AUTOSAR XML (schema 4-0-3)
standard types defined: Boolean, uint8, UInt16, boolean
package /ArPackage_EcuInstance
  ecu instance EcuInstance_explicitinter: com-configuration-gw-time-base=0.005, com-configuration-rx-time-base=0.005, com-configuration-tx-time-base=0.005, com-enable-mdt-for-cyclic-transmission=true, sleep-mode-supported=true, wake-up-over-bus-supported=true
    can communication controller CanCommunicationController_0
    can communication connector CanCommunicationConnector_0: comm-controller=CanCommunicationController_0
  can cluster ComMChannel_CAN1
    can physical channel CanPhysicalChannel_0: comm-connectors=CanCommunicationConnector_0
      frame CanFrame_MMT_tx_200: id 0x200, from EcuInstance_explicitinter, frame-length=8, can-addressing-mode=STANDARD
        pdu ISignalIPdu_MMT_tx_200: length=8, unused-bit-pattern=0
          signal ISignal_MMT_tx_200: start 0, 8 bit, little-endian, data-type-policy=PORT-INTERFACE-DEFINITION, base-type=uint8_base
      frame CanFrame_MMT_tx_201: id 0x201, from EcuInstance_explicitinter, frame-length=8, can-addressing-mode=STANDARD
        pdu ISignalIPdu_MMT_tx_201: length=8, unused-bit-pattern=0
          signal ISignal_MMT_tx_201: start 0, 8 bit, little-endian, data-type-policy=PORT-INTERFACE-DEFINITION, base-type=uint8_base
      frame CanFrame_MMT_tx_210: id 0x210, from EcuInstance_explicitinter, frame-length=8, can-addressing-mode=STANDARD
        pdu ISignalIPdu_MMT_tx_210: length=8, unused-bit-pattern=0
          signal ISignal_MMT_tx_210: start 0, 8 bit, little-endian, data-type-policy=PORT-INTERFACE-DEFINITION
      frame CanFrame_MMT_tx_211: id 0x211, from EcuInstance_explicitinter, frame-length=8, can-addressing-mode=STANDARD
        pdu ISignalIPdu_MMT_tx_211: length=8, unused-bit-pattern=0
          signal ISignal_MMT_tx_211: start 0, 8 bit, little-endian, data-type-policy=PORT-INTERFACE-DEFINITION, base-type=uint8_base
      frame CanFrame_MMT_rx_202: id 0x202, to EcuInstance_explicitinter, frame-length=8, can-addressing-mode=STANDARD
        pdu ISignalIPdu_MMT_rx_202: length=8, unused-bit-pattern=0
          signal ISignal_MMT_rx_202: start 0, 8 bit, little-endian, data-type-policy=PORT-INTERFACE-DEFINITION, base-type=uint8_base, to EcuInstance_explicitinter
      frame CanFrame_MMT_rx_203: id 0x203, to EcuInstance_explicitinter, frame-length=8, can-addressing-mode=STANDARD
        pdu ISignalIPdu_MMT_rx_203: length=8, unused-bit-pattern=0
          signal ISignal_MMT_rx_203: start 0, 8 bit, little-endian, data-type-policy=PORT-INTERFACE-DEFINITION, base-type=uint8_base, to EcuInstance_explicitinter
      frame CanFrame_TC3U8Tx_120: id 0x120, from EcuInstance_explicitinter, frame-length=8, can-addressing-mode=STANDARD
        pdu ISignalIPdu_TC3U8Tx_120: length=8, transmission-mode-condition{data-filter=data-filter-type=ALWAYS, i-signal-in-i-pdu=ISignalIPdu_TC3U8Tx_120/ISignalToIPduMapping_TC3U8Tx}, transmission-mode-true-timing=event-controlled-timing={number-of-repetitions=0, repetition-period=0.0}, unused-bit-pattern=0
          signal ISignal_TC3U8Tx_120: start 0, 8 bit, little-endian, system signal SystemSignal_TC3U8TX_120, data-type-policy=PORT-INTERFACE-DEFINITION, transfer-property=TRIGGERED
      frame CanFrame_TC5ArrTx_121: id 0x121, from EcuInstance_explicitinter, frame-length=8, can-addressing-mode=STANDARD
        pdu ISignalIPdu_TC5ArrTx_121: length=8, transmission-mode-condition{data-filter=data-filter-type=ALWAYS, i-signal-in-i-pdu=ISignalToIPduMapping_TC5ArrTx}, transmission-mode-true-timing=event-controlled-timing={number-of-repetitions=0, repetition-period=0.0}, unused-bit-pattern=0
          mapping ISignalToIPduMapping_TC5ArrTx: i-signal-group=ISignalGroup_TC5ArrTx_121, packing-byte-order=little-endian, start-position=0, transfer-property=TRIGGERED
          mapping ISignalToIPduMapping_TC5Arr0Tx: packing-byte-order=little-endian, start-position=0, transfer-property=TRIGGERED
          mapping ISignalToIPduMapping_TC5Arr1Tx: packing-byte-order=little-endian, start-position=8
          mapping ISignalToIPduMapping_TC5Arr2Tx: packing-byte-order=little-endian, start-position=16
      frame CanFrame_TC6U8Rx_122: id 0x122, to EcuInstance_explicitinter, frame-length=8, can-addressing-mode=STANDARD
        pdu ISignalIPdu_TC6U8Rx_122: length=8, unused-bit-pattern=0
          signal ISignal_TC6U8Rx_122: start 0, 8 bit, little-endian, system signal SystemSignal_TC6U8RX_122, data-type-policy=PORT-INTERFACE-DEFINITION, transfer-property=TRIGGERED, to EcuInstance_explicitinter
      frame CanFrame_TC7Arr8Rx_123: id 0x123, to EcuInstance_explicitinter, frame-length=8, can-addressing-mode=STANDARD
        pdu ISignalIPdu_TC7Arr8Rx_123: length=8, unused-bit-pattern=0
          mapping ISignalToIPduMapping_TC7ArrRx: i-signal-group=ISignalGroup_TC7ArrRx_123, packing-byte-order=little-endian, start-position=0, transfer-property=TRIGGERED
          mapping ISignalToIPduMapping_TC7Arr0Rx: packing-byte-order=little-endian, start-position=0, transfer-property=TRIGGERED
          mapping ISignalToIPduMapping_TC7Arr1Rx: packing-byte-order=little-endian, start-position=8
          mapping ISignalToIPduMapping_TC7Arr2Rx: packing-byte-order=little-endian, start-position=16
      frame CanFrame_TC13U8Tx_126: id 0x126, from EcuInstance_explicitinter, frame-length=8, can-addressing-mode=STANDARD
        pdu ISignalIPdu_TC13U8Tx_126: length=8, transmission-mode-condition{data-filter=data-filter-type=ALWAYS, i-signal-in-i-pdu=ISignalToIPduMapping_TC13U8Tx}, transmission-mode-true-timing=event-controlled-timing={number-of-repetitions=0, repetition-period=0.0}, unused-bit-pattern=0
          signal ISignal_TC13U8Tx_126: start 0, 8 bit, little-endian, data-type-policy=PORT-INTERFACE-DEFINITION, transfer-property=TRIGGERED
      frame CanFrame_TC14Arr8Tx_127: id 0x127, from EcuInstance_explicitinter, frame-length=8, can-addressing-mode=STANDARD
        pdu ISignalIPdu_TC14Arr8Tx_127: length=8, transmission-mode-condition{data-filter=data-filter-type=ALWAYS, i-signal-in-i-pdu=ISignalToIPduMapping_TC14ArrTx}, transmission-mode-true-timing=event-controlled-timing={number-of-repetitions=0, repetition-period=0.0}, unused-bit-pattern=0
          mapping ISignalToIPduMapping_TC14ArrTx: i-signal-group=ISignalGroup_TC14Arr8Tx_127, packing-byte-order=little-endian, start-position=0, transfer-property=TRIGGERED
          mapping ISignalToIPduMapping_TC14Arr0Tx: packing-byte-order=little-endian, start-position=0, transfer-property=TRIGGERED
          mapping ISignalToIPduMapping_TC14Arr1Tx: packing-byte-order=little-endian, start-position=8
          mapping ISignalToIPduMapping_TC14Arr2Tx: packing-byte-order=little-endian, start-position=16
      frame CanFrame_TC15U8RxInv_128: id 0x128, to EcuInstance_explicitinter, frame-length=8, can-addressing-mode=STANDARD
        pdu ISignalIPdu_TC15U8RxInv_128: length=8, unused-bit-pattern=0
          signal ISignal_TC15U8RxInv_128: start 0, 8 bit, little-endian, data-type-policy=PORT-INTERFACE-DEFINITION, transfer-property=TRIGGERED, to EcuInstance_explicitinter
      frame CanFrame_TC16U8RxInvReplace_129: id 0x129, to EcuInstance_explicitinter, frame-length=8, can-addressing-mode=STANDARD
        pdu ISignalIPdu_TC16U8RxInvReplace_129: length=8, unused-bit-pattern=0
          signal ISignal_TC16U8RxInvReplace_129: start 0, 8 bit, little-endian, data-type-policy=PORT-INTERFACE-DEFINITION, transfer-property=TRIGGERED, to EcuInstance_explicitinter
      frame CanFrame_TC17ArrRx_12A: id 0x12A, to EcuInstance_explicitinter, frame-length=8, can-addressing-mode=STANDARD
        pdu ISignalIPdu_TC17ArrRx_12A: length=8, unused-bit-pattern=0
          mapping ISignalToIPduMapping_TC17ArrRx: i-signal-group=ISignalGroup_TC17Arr8Rx_12A, packing-byte-order=little-endian, start-position=0, transfer-property=TRIGGERED
          mapping ISignalToIPduMapping_TC17Arr0Rx: packing-byte-order=little-endian, start-position=0, transfer-property=TRIGGERED
          mapping ISignalToIPduMapping_TC17Arr1Rx: packing-byte-order=little-endian, start-position=8
      frame CanFrame_TC18ArrRx_12B: id 0x12B, to EcuInstance_explicitinter, frame-length=8, can-addressing-mode=STANDARD
        pdu ISignalIPdu_TC18ArrRx_12B: length=8, unused-bit-pattern=0
          mapping ISignalToIPduMapping_TC18ArrRx: i-signal-group=ISignalGroup_TC18Arr8Rx_12B, packing-byte-order=little-endian, start-position=0, transfer-property=TRIGGERED
          mapping ISignalToIPduMapping_TC18Arr0Rx: packing-byte-order=little-endian, start-position=0, transfer-property=TRIGGERED
          mapping ISignalToIPduMapping_TC18Arr1Rx: packing-byte-order=little-endian, start-position=8
          mapping ISignalToIPduMapping_TC18Arr2Rx: packing-byte-order=little-endian, start-position=16
      frame CanFrame_TC19U8Tx_12C: id 0x12C, from EcuInstance_explicitinter, frame-length=8, can-addressing-mode=STANDARD
        pdu ISignalIPdu_TC19U8Tx_12C: length=8, transmission-mode-condition{data-filter=data-filter-type=ALWAYS, i-signal-in-i-pdu=ISignalToIPduMapping_TC19Tx}, transmission-mode-true-timing=event-controlled-timing={number-of-repetitions=0, repetition-period=0.0}, unused-bit-pattern=0
          signal ISignal_TC19U8Tx_12C: start 0, 8 bit, little-endian, data-type-policy=PORT-INTERFACE-DEFINITION, transfer-property=TRIGGERED
      frame CanFrame_TC21U8Tx_250: id 0x250, from EcuInstance_explicitinter, frame-length=8, can-addressing-mode=STANDARD
        pdu ISignalIPdu_TC21U8Tx_250: length=8, transmission-mode-condition{data-filter=data-filter-type=ALWAYS, i-signal-in-i-pdu=ISignalToIPduMapping_TC21}, transmission-mode-true-timing=event-controlled-timing={number-of-repetitions=0, repetition-period=0.0}, unused-bit-pattern=0
          signal ISignal_TC21U8Tx_250: start 0, 8 bit, little-endian, data-type-policy=PORT-INTERFACE-DEFINITION, transfer-property=TRIGGERED
      frame CanFrame_TC23U8Tx_149: id 0x149, from EcuInstance_explicitinter, frame-length=8, can-addressing-mode=STANDARD
        pdu ISignalIPdu_TC23U8Tx_149: length=8, transmission-mode-condition{data-filter=data-filter-type=ALWAYS, i-signal-in-i-pdu=ISignalToIPduMapping_TC23}, transmission-mode-true-timing=event-controlled-timing={number-of-repetitions=0, repetition-period=0.0}, unused-bit-pattern=0
          signal ISignal_TC23U8Tx_149: start 0, 8 bit, little-endian, data-type-policy=PORT-INTERFACE-DEFINITION, transfer-property=TRIGGERED
      frame CanFrame_TC26Arr8Tx_12F: id 0x12F, from EcuInstance_explicitinter, frame-length=8, can-addressing-mode=STANDARD
        pdu ISignalIPdu_TC26Arr8Tx_12F: length=8, transmission-mode-condition{data-filter=data-filter-type=ALWAYS, i-signal-in-i-pdu=ISignalToIPduMapping_TC26ArrTx}, transmission-mode-true-timing=event-controlled-timing={number-of-repetitions=0, repetition-period=0.0}, unused-bit-pattern=0
          mapping ISignalToIPduMapping_TC26ArrTx: i-signal-group=ISignalGroup_TC26Arr8Tx_12F, packing-byte-order=little-endian, start-position=0, transfer-property=TRIGGERED
          mapping ISignalToIPduMapping_TC26Arr0Tx: packing-byte-order=little-endian, start-position=0, transfer-property=TRIGGERED
          mapping ISignalToIPduMapping_TC26Arr1Tx: packing-byte-order=little-endian, start-position=8
      frame CanFrame_TC28Arr8Tx_252: id 0x252, from EcuInstance_explicitinter, frame-length=8, can-addressing-mode=STANDARD
        pdu ISignalIPdu_TC28Arr8Tx_252: length=8, transmission-mode-condition{data-filter=data-filter-type=ALWAYS, i-signal-in-i-pdu=ISignalToIPduMapping_TC28ArrTx}, transmission-mode-true-timing=event-controlled-timing={number-of-repetitions=0, repetition-period=0.0}, unused-bit-pattern=0
          mapping ISignalToIPduMapping_TC28ArrTx: i-signal-group=ISignalGroup_TC28Arr8Tx_252, packing-byte-order=little-endian, start-position=0, transfer-property=TRIGGERED
          mapping ISignalToIPduMapping_TC28Arr0Tx: packing-byte-order=little-endian, start-position=0, transfer-property=TRIGGERED
          mapping ISignalToIPduMapping_TC28Arr1Tx: packing-byte-order=little-endian, start-position=8
      frame CanFrame_TC30Arr8Tx_14B: id 0x14B, from EcuInstance_explicitinter, frame-length=8, can-addressing-mode=STANDARD
        pdu ISignalIPdu_TC30Arr8Tx_14B: length=8, transmission-mode-condition{data-filter=data-filter-type=ALWAYS, i-signal-in-i-pdu=ISignalToIPduMapping_TC30ArrTx}, transmission-mode-true-timing=event-controlled-timing={number-of-repetitions=0, repetition-period=0.0}, unused-bit-pattern=0
          mapping ISignalToIPduMapping_TC30ArrTx: i-signal-group=ISignalGroup_TC30Arr8Tx_14B, packing-byte-order=little-endian, start-position=0, transfer-property=TRIGGERED
          mapping ISignalToIPduMapping_TC30Arr0Tx: packing-byte-order=little-endian, start-position=0, transfer-property=TRIGGERED
          mapping ISignalToIPduMapping_TC30Arr1Tx: packing-byte-order=little-endian, start-position=8
      frame CanFrame_TC34U8Rx_132: id 0x132, to EcuInstance_explicitinter, frame-length=8, can-addressing-mode=STANDARD
        pdu ISignalIPdu_TC34U8Rx_132: length=8, unused-bit-pattern=0
          signal ISignal_TC34U8Rx_132: start 0, 8 bit, little-endian, data-type-policy=PORT-INTERFACE-DEFINITION, transfer-property=TRIGGERED, to EcuInstance_explicitinter
      frame CanFram_TC36U8Tx_133: id 0x133, from EcuInstance_explicitinter, frame-length=8, can-addressing-mode=STANDARD
        pdu ISignalIPdu_TC36U8Tx_133: length=8, transmission-mode-condition{data-filter=data-filter-type=ALWAYS, i-signal-in-i-pdu=ISignalToIPduMapping_TC36}, transmission-mode-true-timing=event-controlled-timing={number-of-repetitions=0, repetition-period=0.0}, unused-bit-pattern=0
          signal ISignal_TC36U8Tx_133: start 0, 8 bit, little-endian, data-type-policy=PORT-INTERFACE-DEFINITION, transfer-property=TRIGGERED
      frame CanFrame_TC37U8Tx_254: id 0x254, from EcuInstance_explicitinter, frame-length=8, can-addressing-mode=STANDARD
        pdu ISignalIPdu_TC37U8Tx_254: length=8, transmission-mode-condition{data-filter=data-filter-type=ALWAYS, i-signal-in-i-pdu=ISignalToIPduMapping_TC37}, transmission-mode-true-timing=event-controlled-timing={number-of-repetitions=0, repetition-period=0.0}, unused-bit-pattern=0
          signal ISignal_TC37U8Tx_254: start 0, 8 bit, little-endian, data-type-policy=PORT-INTERFACE-DEFINITION, transfer-property=TRIGGERED
      frame CanFrame_TC38U8Rx_134: id 0x134, to EcuInstance_explicitinter, frame-length=8, can-addressing-mode=STANDARD
        pdu ISignalIPdu_TC38U8Rx_134: length=8, unused-bit-pattern=0
          signal ISignal_TC38U8Rx_134: start 0, 8 bit, little-endian, data-type-policy=PORT-INTERFACE-DEFINITION, transfer-property=TRIGGERED, to EcuInstance_explicitinter
      frame CanFrame_TC32Arr8Rx_131: id 0x131, to EcuInstance_explicitinter, frame-length=8, can-addressing-mode=STANDARD
        pdu ISignalIPdu_TC32Arr8Rx_131: length=8, unused-bit-pattern=0
          mapping ISignalToIPduMapping_TC32ArrRx: i-signal-group=ISignalGroup_TC32Arr8Rx_131, packing-byte-order=little-endian, start-position=0, transfer-property=TRIGGERED
          mapping ISignalToIPduMapping_TC32Arr0Rx: packing-byte-order=little-endian, start-position=0, transfer-property=TRIGGERED
          mapping ISignalToIPduMapping_TC32Arr1Rx: packing-byte-order=little-endian, start-position=8
      frame CanFrame_TC22U8Tx_251: id 0x251, from EcuInstance_explicitinter, frame-length=8, can-addressing-mode=STANDARD
        pdu ISignalIPdu_TC22U8Tx_251: length=8, transmission-mode-condition{data-filter=data-filter-type=ALWAYS, i-signal-in-i-pdu=ISignalToIPduMapping_TC22U8Tx}, transmission-mode-true-timing=event-controlled-timing={number-of-repetitions=0, repetition-period=0.0}, unused-bit-pattern=0
          signal ISignal_TC22U8Tx_251: start 0, 8 bit, little-endian, data-type-policy=PORT-INTERFACE-DEFINITION, transfer-property=TRIGGERED
      frame CanFrame_TC20U8Tx_12D: id 0x12D, from EcuInstance_explicitinter, frame-length=8, can-addressing-mode=STANDARD
        pdu ISignalIPdu_TC20U8Tx_12D: length=8, transmission-mode-condition{data-filter=data-filter-type=ALWAYS, i-signal-in-i-pdu=ISignalToIPduMapping_TC20U8Tx}, transmission-mode-true-timing=event-controlled-timing={number-of-repetitions=0, repetition-period=0.0}, unused-bit-pattern=0
          signal ISignal_TC20U8Tx_12D: start 0, 8 bit, little-endian, data-type-policy=PORT-INTERFACE-DEFINITION, transfer-property=TRIGGERED
      frame CanFrame_TC24U8Tx_14A: id 0x14A, from EcuInstance_explicitinter, frame-length=8, can-addressing-mode=STANDARD
        pdu ISignalIPdu_TC24U8Tx_14A: length=8, transmission-mode-condition{data-filter=data-filter-type=ALWAYS, i-signal-in-i-pdu=ISignalToIPduMapping_TC24U8Tx}, transmission-mode-true-timing=event-controlled-timing={number-of-repetitions=0, repetition-period=0.0}, unused-bit-pattern=0
          signal ISignal_TC24U8Tx_14A: start 0, 8 bit, little-endian, data-type-policy=PORT-INTERFACE-DEFINITION, transfer-property=TRIGGERED
      frame CanFrame_TC27Arr8Tx_130: id 0x130, from EcuInstance_explicitinter, frame-length=8, can-addressing-mode=STANDARD
        pdu ISignalIPdu_TC27Arr8Tx_130: length=8, transmission-mode-condition{data-filter=data-filter-type=ALWAYS, i-signal-in-i-pdu=ISignalToIPduMapping_TC27ArrTx}, transmission-mode-true-timing=event-controlled-timing={number-of-repetitions=0, repetition-period=0.0}, unused-bit-pattern=0
          mapping ISignalToIPduMapping_TC27ArrTx: i-signal-group=ISignalGroup_TC27Arr8Tx_130, packing-byte-order=little-endian, start-position=0, transfer-property=TRIGGERED
          mapping ISignalToIPduMapping_TC27Arr0Tx: packing-byte-order=little-endian, start-position=0, transfer-property=TRIGGERED
          mapping ISignalToIPduMapping_TC27Arr1Tx: packing-byte-order=little-endian, start-position=8, transfer-property=TRIGGERED
          mapping ISignalToIPduMapping_TC27Arr2Tx: packing-byte-order=little-endian, start-position=16, transfer-property=TRIGGERED
      frame CanFrame_TC29Arr8Tx_253: id 0x253, from EcuInstance_explicitinter, frame-length=8, can-addressing-mode=STANDARD
        pdu ISignalIPdu_TC29Arr8Tx_253: length=8, transmission-mode-condition{data-filter=data-filter-type=ALWAYS, i-signal-in-i-pdu=ISignalToIPduMappingTC29Arr8Tx}, transmission-mode-true-timing=event-controlled-timing={number-of-repetitions=0, repetition-period=0.0}, unused-bit-pattern=0
          mapping ISignalToIPduMappingTC29Arr8Tx: i-signal-group=ISignalGroup_TC29Arr8Tx_253, packing-byte-order=little-endian, start-position=0, transfer-property=TRIGGERED
          mapping ISignalToIPduMappingTC29Arr0Tx: packing-byte-order=little-endian, start-position=0, transfer-property=TRIGGERED
          mapping ISignalToIPduMappingTC29Arr1Tx: packing-byte-order=little-endian, start-position=8
      frame CanFrame_TC31Arr8Tx_14C: id 0x14C, from EcuInstance_explicitinter, frame-length=8, can-addressing-mode=STANDARD
        pdu ISignalIPdu_TC31Arr8Tx_14C: length=8, transmission-mode-condition{data-filter=data-filter-type=ALWAYS, i-signal-in-i-pdu=ISignalToIPduMapping_TC28ArrTx}, transmission-mode-true-timing=event-controlled-timing={number-of-repetitions=0, repetition-period=0.0}, unused-bit-pattern=0
          mapping ISignalToIPduMapping_TC31Arr8Tx: i-signal-group=ISignalGroup_TC31Arr8Tx_14C, packing-byte-order=little-endian, start-position=0, transfer-property=TRIGGERED
          mapping ISignalToIPduMapping_TC31Arr0Tx: packing-byte-order=little-endian, start-position=0, transfer-property=TRIGGERED
          mapping ISignalToIPduMapping_TC31Arr1Tx: packing-byte-order=little-endian, start-position=8
      frame CanFrame_TC40U8Rx_136: id 0x136, to EcuInstance_explicitinter, frame-length=8, can-addressing-mode=STANDARD
        pdu ISignalIPdu_TC40U8Rx_136: length=8, unused-bit-pattern=0
          signal ISignal_TC40U8Rx_136: start 0, 8 bit, little-endian, data-type-policy=PORT-INTERFACE-DEFINITION, transfer-property=TRIGGERED, to EcuInstance_explicitinter
      frame CanFrame_TC41U8Rx_137: id 0x137, to EcuInstance_explicitinter, frame-length=8, can-addressing-mode=STANDARD
        pdu ISignalIPdu_TC41U8Rx_137: length=8, unused-bit-pattern=0
          signal ISignal_TC41U8Rx_137: start 0, 8 bit, little-endian, data-type-policy=PORT-INTERFACE-DEFINITION, transfer-property=TRIGGERED, to EcuInstance_explicitinter
      frame CanFrame_TC39Arr8Rx_135: id 0x135, to EcuInstance_explicitinter, frame-length=8, can-addressing-mode=STANDARD
        pdu ISignalIPdu_TC39Arr8Rx_135: length=8, unused-bit-pattern=0
          mapping ISignalToIPduMapping_TC39ArrRx: i-signal-group=ISignalGroup_TC39Arr8Rx_135, packing-byte-order=little-endian, start-position=0, transfer-property=TRIGGERED
          mapping ISignalToIPduMapping_TC39Arr0Rx: packing-byte-order=little-endian, start-position=0, transfer-property=TRIGGERED
          mapping ISignalToIPduMapping_TC39Arr1Rx: packing-byte-order=little-endian, start-position=8
          mapping ISignalToIPduMapping_TC39Arr2Rx: packing-byte-order=little-endian, start-position=16
      frame CanFrame_TC8DynArruint8_124: id 0x124, from EcuInstance_explicitinter, frame-length=8, can-addressing-mode=STANDARD
        pdu ISignalIPdu_TC8DynArruint8_124: length=8, transmission-mode-condition{data-filter=data-filter-type=ALWAYS, i-signal-in-i-pdu=ISignalToIPduMapping_TC8DynArruint8}, transmission-mode-true-timing=event-controlled-timing={number-of-repetitions=0, repetition-period=0.0}, unused-bit-pattern=0
          signal ISignal_TC8DynArruint8_124: start 0, 64 bit, little-endian, data-type-policy=PORT-INTERFACE-DEFINITION, dynamic-length=true, transfer-property=TRIGGERED
      frame CanFrame_TC9DynArruint8_125: id 0x125, to EcuInstance_explicitinter, frame-length=8, can-addressing-mode=STANDARD
        pdu ISignalIPdu_TC9DynArruint8_125: length=8, unused-bit-pattern=0
          signal ISignal_TC9DynArruint8_125: start 0, 64 bit, little-endian, data-type-policy=PORT-INTERFACE-DEFINITION, dynamic-length=true, transfer-property=TRIGGERED, to EcuInstance_explicitinter
      frame CanFrame_TC25U8RX_12E: id 0x12E, to EcuInstance_explicitinter, frame-length=8, can-addressing-mode=STANDARD
        pdu ISignalIPdu_TC25U8RX_12E: length=8, unused-bit-pattern=0
          signal ISignal_TC25U8RX_12E: start 0, 8 bit, little-endian, data-type-policy=PORT-INTERFACE-DEFINITION, transfer-property=TRIGGERED, to EcuInstance_explicitinter
      frame CanFrame_NmPdu_RX: id 0x7F0, to EcuInstance_explicitinter, frame-length=8, can-addressing-mode=STANDARD
        nm pdu NmPdu_RX: length=8, nm-data-information=false, nm-vote-information=false, unused-bit-pattern=0
      frame CanFrame_NmPdu_TX: id 0x7F1, from EcuInstance_explicitinter, frame-length=8, can-addressing-mode=STANDARD
        nm pdu NmPdu_TX: length=8, nm-data-information=false, nm-vote-information=false, unused-bit-pattern=0
package /ArPackage_ComM
  impl type ComM_ModeType: category=VALUE, base-type=uint8_base, data-constr=DataConstr_0
  data constr DataConstr_0
  client server interface ComM_UserRequest: is-service=true, service-kind=COM-MANAGER
    4 x operation:
      RequestComMode: possible-error=[ComM_UserRequest/E_NOT_OK, E_MODE_LIMITATION]
        arg ComMode: type=ComM_ModeType, direction=IN
      GetCurrentComMode: possible-error=ComM_UserRequest/E_NOT_OK
        arg ComMode: type=ComM_ModeType, direction=OUT
      GetMaxComMode: possible-error=ComM_UserRequest/E_NOT_OK
        arg ComMode: type=ComM_ModeType, direction=OUT
      GetRequestedComMode: possible-error=ComM_UserRequest/E_NOT_OK
        arg ComMode: type=ComM_ModeType, direction=OUT
    error E_NOT_OK: error-code=1
    error E_MODE_LIMITATION: error-code=2
  client server interface ComM_ECUModeLimitation: is-service=true, service-kind=COM-MANAGER
    4 x operation, all with possible-error=ComM_ECUModeLimitation/E_NOT_OK:
      LimitECUToNoComMode
        arg Status: type=Boolean, direction=IN
      ReadInhibitCounter
        arg CounterValue: type=UInt16, direction=OUT
      ResetInhibitCounter
      SetECUGroupClassification
        arg Status: type=ComM_InhibitionStatusType, direction=IN
    error E_NOT_OK: error-code=1
  data type mapping set DataTypeMappingSet_0: mode-request-type-map{implementation-data-type=ComM_ModeType, mode-group=ComMMode}
  mode declaration group ComMMode: initial-mode=COMM_NO_COMMUNICATION
    mode COMM_NO_COMMUNICATION
    mode COMM_SILENT_COMMUNICATION
    mode COMM_FULL_COMMUNICATION
  mode switch interface ComM_CurrentMode: is-service=true, service-kind=COM-MANAGER
    mode group currentMode: type=ComMMode
  sender receiver interface ComM_CurrentChannelRequest
    data fullComRequestors: type=ComM_UserHandleArrayType
  impl type ComM_UserHandleArrayType: category=STRUCTURE
    element numberOfRequesters: category=VALUE, base-type=uint8_base
    element handleArray: implementation-data-type=ComM_UserHandleType_array
  impl type ComM_UserHandleType_array: category=ARRAY
  client server interface ComM_ChannelWakeup: is-service=true, service-kind=COM-MANAGER
    operation PreventWakeUp: possible-error=ComM_ChannelWakeup/E_NOT_OK
      arg Status: type=Boolean, direction=IN
    error E_NOT_OK: error-code=1
  client server interface ComM_ChannelLimitation: is-service=true, service-kind=COM-MANAGER
    operation LimitChannelToNoComMode: possible-error=ComM_ChannelLimitation/E_NOT_OK
      arg Status: type=Boolean, direction=IN
    operation GetInhibitionStatus: possible-error=ComM_ChannelLimitation/E_NOT_OK
      arg Status: type=ComM_InhibitionStatusType, direction=OUT
    error E_NOT_OK: error-code=1
  impl type ComM_InhibitionStatusType: category=VALUE, base-type=uint8_base
  data constr DataConstr_2
  impl type ComM_UserHandleType: category=VALUE
  data constr DataConstr_1
package /ArPackage_NvM
  client server interface NvMAdmin: is-service=true, service-kind=NON-VOLATILE-RAM-MANAGER
    operation SetBlockProtection: possible-error=NvMAdmin/E_NOT_OK
      arg ArgumentDataPrototype_0: type=boolean, direction=IN
    error E_NOT_OK: error-code=1
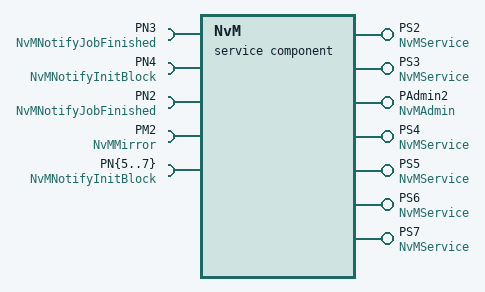
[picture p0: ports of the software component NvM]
  service sw component type NvM
    7 x provide port:
      PS2: provided-interface=NvMService
        provided-com-specs:
          queue-length=1
          operation=SetDataIndex, queue-length=1
          operation=GetDataIndex, queue-length=1
          operation=SetRamBlockStatus, queue-length=1
          operation=ReadBlock, queue-length=1
          operation=WriteBlock, queue-length=1
          operation=RestoreBlockDefaults, queue-length=1
          operation=EraseBlock, queue-length=1
          operation=InvalidateNvBlock, queue-length=1
      PS3: provided-interface=NvMService
        provided-com-specs:
          operation=GetErrorStatus, queue-length=1
          operation=SetDataIndex, queue-length=1
          operation=GetDataIndex, queue-length=1
          operation=SetRamBlockStatus, queue-length=1
          operation=ReadBlock, queue-length=1
          operation=WriteBlock, queue-length=1
          operation=RestoreBlockDefaults, queue-length=1
          operation=EraseBlock, queue-length=1
          operation=InvalidateNvBlock, queue-length=1
      PAdmin2: server-com-spec{operation=SetBlockProtection, queue-length=1}, provided-interface=NvMAdmin
      PS4: provided-interface=NvMService
        provided-com-specs:
          operation=GetErrorStatus, queue-length=1
          operation=SetDataIndex, queue-length=1
          operation=GetDataIndex, queue-length=1
          operation=SetRamBlockStatus, queue-length=1
          operation=ReadBlock, queue-length=1
          operation=WriteBlock, queue-length=1
          operation=RestoreBlockDefaults, queue-length=1
          operation=EraseBlock, queue-length=1
          operation=InvalidateNvBlock, queue-length=1
          operation=CancelJobs, queue-length=1
      PS5: provided-interface=NvMService
        provided-com-specs:
          operation=GetErrorStatus, queue-length=1
          operation=SetDataIndex, queue-length=1
          operation=GetDataIndex, queue-length=1
          operation=SetRamBlockStatus, queue-length=1
          operation=ReadBlock, queue-length=1
          operation=WriteBlock, queue-length=1
          operation=RestoreBlockDefaults, queue-length=1
          operation=EraseBlock, queue-length=1
          operation=InvalidateNvBlock, queue-length=1
          operation=CancelJobs, queue-length=1
      PS6: provided-interface=NvMService
        provided-com-specs:
          operation=GetErrorStatus, queue-length=1
          operation=SetDataIndex, queue-length=1
          operation=GetDataIndex, queue-length=1
          operation=SetRamBlockStatus, queue-length=1
          operation=ReadBlock, queue-length=1
          operation=WriteBlock, queue-length=1
          operation=RestoreBlockDefaults, queue-length=1
          operation=EraseBlock, queue-length=1
          operation=InvalidateNvBlock, queue-length=1
          operation=CancelJobs, queue-length=1
      PS7: provided-interface=NvMService
        provided-com-specs:
          operation=GetErrorStatus, queue-length=1
          operation=SetDataIndex, queue-length=1
          operation=GetDataIndex, queue-length=1
          operation=SetRamBlockStatus, queue-length=1
          operation=ReadBlock, queue-length=1
          operation=WriteBlock, queue-length=1
          operation=RestoreBlockDefaults, queue-length=1
          operation=EraseBlock, queue-length=1
          operation=InvalidateNvBlock, queue-length=1
          operation=CancelJobs, queue-length=1
    7 x require port:
      PN3: client-com-spec=JobFinished, required-interface=NvMNotifyJobFinished
      PN4: client-com-spec=InitBlock, required-interface=NvMNotifyInitBlock
      PN2: client-com-spec=JobFinished, required-interface=NvMNotifyJobFinished
      PM2: required-com-specs=[ReadRamBlockFromNvm, WriteRamBlockToNvm], required-interface=NvMMirror
      PN{5..7}: client-com-spec=InitBlock, required-interface=NvMNotifyInitBlock
    behavior IB_NvM: handle-termination-and-restart=CAN-BE-TERMINATED-AND-RESTARTED
      10 x operation invoked event:
        OperationInvokedEvent_0: start-on-event=GetErrorStatus, operation=PS2.GetErrorStatus
        OperationInvokedEvent_1: start-on-event=SetDataIndex, operation=PS2.SetDataIndex
        OperationInvokedEvent_2: start-on-event=GetDataIndex, operation=PS2.GetDataIndex
        OperationInvokedEvent_3: start-on-event=SetRamBlockStatus, operation=PS2.SetRamBlockStatus
        OperationInvokedEvent_4: start-on-event=ReadBlock, operation=PS2.ReadBlock
        OperationInvokedEvent_5: start-on-event=WriteBlock, operation=PS2.WriteBlock
        OperationInvokedEvent_6: start-on-event=RestoreBlockDefaults, operation=PS2.RestoreBlockDefaults
        OperationInvokedEvent_7: start-on-event=EraseNvBlock, operation=PS2.EraseBlock
        OperationInvokedEvent_8: start-on-event=InvalidateNvBlock, operation=PS2.InvalidateNvBlock
        OperationInvokedEvent_9: start-on-event=SetBlockProtection, operation=PAdmin2.SetBlockProtection
      port-api-options:
        {enable-take-address=false, indirect-api=false, port-defined-argument-value{value=Block2:2, value-type=NvM_BlockIdType}, port=PS2}
        {enable-take-address=false, indirect-api=false, port-defined-argument-value{value=Block3:3, value-type=NvM_BlockIdType}, port=PS3}
        {enable-take-address=false, indirect-api=false, port-defined-argument-value{value=Block2:2, value-type=NvM_BlockIdType}, port=PAdmin2}
      10 x runnable, all with can-be-invoked-concurrently=true:
        GetErrorStatus: symbol=NvM_GetErrorStatus
        SetDataIndex: symbol=NvM_SetDataIndex
        GetDataIndex: symbol=NvM_GetDataIndex
        SetRamBlockStatus: symbol=NvM_SetRamBlockStatus
        ReadBlock: symbol=NvM_ReadBlock
        WriteBlock: symbol=NvM_WriteBlock
        RestoreBlockDefaults: symbol=NvM_RestoreBlockDefaults
        EraseNvBlock: symbol=NvM_EraseNvBlock
        InvalidateNvBlock: symbol=NvM_InvalidateNvBlock
        SetBlockProtection: symbol=NvM_SetBlockProtection
  client server interface NvMService: is-service=true, service-kind=NON-VOLATILE-RAM-MANAGER
    10 x operation, all with possible-error=NvMService/E_NOT_OK:
      GetErrorStatus
        arg ArgumentDataPrototype_0: type=NvM_RequestResultType, direction=OUT
      SetDataIndex
        arg ArgumentDataPrototype_0: type=ArPackage_NvM/uint8, direction=IN
      GetDataIndex
        arg ArgumentDataPrototype_0: type=ArPackage_NvM/uint8, direction=OUT
      SetRamBlockStatus
        arg ArgumentDataPrototype_0: type=ArPackage_NvM/uint8, direction=IN
      ReadBlock
        arg ArgumentDataPrototype_0: type=Arr8, direction=IN, server-argument-impl-policy=USE-VOID
      WriteBlock
        arg ArgumentDataPrototype_0: type=Arr8, direction=IN, server-argument-impl-policy=USE-VOID
      RestoreBlockDefaults
        arg ArgumentDataPrototype_0: type=Arr8, direction=IN, server-argument-impl-policy=USE-VOID
      EraseBlock
      InvalidateNvBlock
      CancelJobs
    error E_NOT_OK: error-code=1
  impl type NvM_RequestResultType: category=VALUE, base-type=uint8_base, compu {0=NVM_REQ_OK (EngObject), 1=NVM_REQ_NOT_OK, 2=NVM_REQ_PENDING, 3=NVM_REQ_INTEGRITY_FAILED, 4=NVM_REQ_BLOCK_SKIPPED, 5=NVM_REQ_NV_INVALIDATED, 6=NVM_REQ_CANCELED, 7=NVM_REQ_REDUNDANCY_FAILED, 8=NVM_REQ_RESTORED_FROM_ROM}
  client server interface NvMNotifyJobFinished: is-service=true, service-kind=NON-VOLATILE-RAM-MANAGER
    operation JobFinished
      arg ArgumentDataPrototype_0: type=ArPackage_NvM/uint8, direction=IN
      arg ArgumentDataPrototype_1: type=NvM_RequestResultType, direction=IN
  impl type Arr8: category=ARRAY
    element ImplementationDataTypeElement_0: category=VALUE, array-size=8, array-size-semantics=FIXED-SIZE, base-type=uint8_base
  client server interface NvMMirror: is-service=true, service-kind=NON-VOLATILE-RAM-MANAGER
    operation ReadRamBlockFromNvm: possible-error=NvMMirror/E_NOT_OK
      arg ArgumentDataPrototype_0: type=Arr8, direction=IN, server-argument-impl-policy=USE-VOID
    operation WriteRamBlockToNvm: possible-error=NvMMirror/E_NOT_OK
      arg ArgumentDataPrototype_0: type=Arr8, direction=IN, server-argument-impl-policy=USE-VOID
    error E_NOT_OK: error-code=1
  impl type NvM_BlockIdType: category=VALUE
  client server interface NvMNotifyInitBlock: is-service=true, service-kind=NON-VOLATILE-RAM-MANAGER
    operation InitBlock
package /ArPackage_BswM
  data type mapping set DataTypeMappingSet_1: mode-request-type-map=EcuM_StateType
  sender receiver interface AppModeRequestInterface: is-service=true, service-kind=BASIC-SOFTWARE-MODE-MANAGER
    data requestedMode: type=AppModeRequestType
  impl type AppModeRequestType: category=VALUE, base-type=uint8_base, data-constr=DataConstr_AppModeRequestType
  data constr DataConstr_AppModeRequestType
  data type mapping set DataTypeMappingSet_0: mode-request-type-map=AppModeRequestType
package /ArPackage_System
  system System_Minimal: system-version=4.0.3
    system mapping SystemMapping_ExplicitInter
      data-mappings:
        sender-receiver-to-signal-group-mapping={data-element=TopLevelComposition.PPortPrototype_TC5.VariableDataPrototype_TC5, signal-group=SystemSignalGroup_TC5ArrTx_121}
        sender-receiver-to-signal-group-mapping={data-element=TopLevelComposition.VariableDataPrototype_TC7, signal-group=SystemSignalGroup_TC7ArrRx_123}
        sender-receiver-to-signal-group-mapping={data-element=TopLevelComposition.PPortPrototype_TC14.VariableDataPrototype_TC14, signal-group=SystemSignalGroup_TC14Arr8Tx_127}
        sender-receiver-to-signal-group-mapping={data-element=TopLevelComposition.RPortPrototype_TC17.VariableDataPrototype_TC17, signal-group=SystemSignaGroupl_TC17Arr8Rx_12A}
        sender-receiver-to-signal-group-mapping={data-element=TopLevelComposition.PPortPrototype_TC26.VariableDataPrototype_TC26, signal-group=SystemSignalGroup_TC26Arr8Tx_12F}
        sender-receiver-to-signal-group-mapping={data-element=TopLevelComposition.PPortPrototype_TC28.VariableDataPrototype_TC28, signal-group=SystemSignalGroup_TC28Arr8Tx_252}
        sender-receiver-to-signal-group-mapping={data-element=TopLevelComposition.PPortPrototype_TC30.VariableDataPrototype_TC30, signal-group=SystemSignalGroup_TC30Arr8Tx_14B}
        sender-receiver-to-signal-group-mapping={data-element=TopLevelComposition.RPortPrototype_TC32.VariableDataPrototype_TC32, signal-group=SystemSignalGroup_TC32Arr8Rx_131}
        sender-receiver-to-signal-group-mapping={data-element=TopLevelComposition.PPortPrototype_TC27.VariableDataPrototype_TC27, signal-group=SystemSignalGroup_TC27Arr8Tx_130}
        sender-receiver-to-signal-group-mapping={data-element=TopLevelComposition.PPortPrototype_TC29.VariableDataPrototype_TC29, signal-group=SystemSignalGroup_TC29Arr8Tx_253}
        sender-receiver-to-signal-group-mapping={data-element=TopLevelComposition.PPortPrototype_TC31.VariableDataPrototype_TC31, signal-group=SystemSignalGroup_TC31Arr8Tx_14C}
        sender-receiver-to-signal-mapping={data-element=TopLevelComposition.VariableDataPrototype_0, system-signal=SystemSignal_MMT_tx_200}
        sender-receiver-to-signal-mapping={data-element=TopLevelComposition.Appl_frame_tx201.VariableDataPrototype_0, system-signal=SystemSignal_MMT_tx_201}
        sender-receiver-to-signal-mapping={data-element=TopLevelComposition.Appl_frame_tx210.VariableDataPrototype_0, system-signal=SystemSignal_MMT_tx_210}
        sender-receiver-to-signal-mapping={data-element=TopLevelComposition.Appl_frame_tx211.VariableDataPrototype_0, system-signal=SystemSignal_MMT_tx_211}
        sender-receiver-to-signal-mapping={data-element=TopLevelComposition.Appl_frame_rx203.VariableDataPrototype_0, system-signal=SystemSignal_MMT_rx_203}
        sender-receiver-to-signal-mapping={data-element=TopLevelComposition.Appl_frame_rx202.VariableDataPrototype_0, system-signal=SystemSignal_MMT_rx_202}
        sender-receiver-to-signal-mapping={data-element=TopLevelComposition.PPortPrototype_TC23.VariableDataPrototype_TC23, system-signal=SystemSignal_TC23U8Tx_149}
        sender-receiver-to-signal-mapping={data-element=TopLevelComposition.PPortPrototype_TC13.VariableDataPrototype_TC13, system-signal=SystemSignal_TC13U8Tx_126}
        sender-receiver-to-signal-mapping={data-element=TopLevelComposition.RPortPrototype_TC6.VariableDataPrototype_TC6, system-signal=SystemSignal_TC6U8RX_122}
        sender-receiver-to-signal-mapping={data-element=TopLevelComposition.RPortPrototype_TC15.VariableDataPrototype_TC15, system-signal=SystemSignal_TC15U8RxInv_128}
        sender-receiver-to-signal-mapping={data-element=TopLevelComposition.RPortPrototype_TC34.VariableDataPrototype_TC34, system-signal=SystemSignal_TC34U8Rx_132}
        sender-receiver-to-signal-mapping={data-element=TopLevelComposition.PPortPrototype_TC36.VariableDataPrototype_TC36, system-signal=SystemSignal_TC36U8Tx_133}
        sender-receiver-to-signal-mapping={data-element=TopLevelComposition.PPortPrototype_TC37.VariableDataPrototype_TC37, system-signal=SystemSignal_TC37U8Tx_254}
        sender-receiver-to-signal-mapping={data-element=TopLevelComposition.RPortPrototype_TC38.VariableDataPrototype_TC38, system-signal=SystemSignal_TC38U8Rx_134}
        sender-receiver-to-signal-mapping={data-element=TopLevelComposition.RPortPrototype_TC16.VariableDataPrototype_TC16, system-signal=SystemSignal_TC16U8RxInvReplace_129}
        sender-receiver-to-signal-mapping={data-element=TopLevelComposition.PPortPrototype_TC22.VariableDataPrototype_TC22, system-signal=SystemSignal_TC22U8Tx_251}
        sender-receiver-to-signal-mapping={data-element=TopLevelComposition.PPortPrototype_TC20.VariableDataPrototype_TC20, system-signal=SystemSignal_TC20U8Tx_12D}
        sender-receiver-to-signal-mapping={data-element=TopLevelComposition.PPortPrototype_TC24.VariableDataPrototype_TC24, system-signal=SystemSignal_TC24U8Tx_14A}
        sender-receiver-to-signal-mapping={data-element=TopLevelComposition.PPortPrototype_TC3.VariableDataPrototype_TC3, system-signal=SystemSignal_TC3U8TX_120}
        sender-receiver-to-signal-mapping={data-element=TopLevelComposition.PPortPrototype_TC19.VariableDataPrototype_TC19, system-signal=SystemSignal_TC19U8Tx_12C}
        sender-receiver-to-signal-mapping={data-element=TopLevelComposition.PPortPrototype_TC21.VariableDataPrototype_TC21, system-signal=SystemSignal_TC21U8Tx_250}
        sender-receiver-to-signal-mapping={data-element=TopLevelComposition.RPortPrototype_TC40.VariableDataPrototype_TC40, system-signal=SystemSignal_TC40U8Rx_136}
        sender-receiver-to-signal-mapping={data-element=TopLevelComposition.RPortPrototype_TC41.VariableDataPrototype_TC41, system-signal=SystemSignal_TC41U8Rx_137}
        sender-receiver-to-signal-mapping={data-element=C_ExplicitInter.TopLevelComposition.PPortPrototype_TC8.VariableDataPrototype_TC8, system-signal=SystemSignal_TC8DynArruint8_124}
        sender-receiver-to-signal-mapping={data-element=C_ExplicitInter.TopLevelComposition.RPortPrototype_TC9.VariableDataPrototype_TC9, system-signal=SystemSignal_TC9DynArruint8_125}
        sender-receiver-to-signal-mapping={data-element=C_ExplicitInter.TopLevelComposition.RPortPrototype_TC25.VariableDataPrototype_TC25, system-signal=SystemSignal_TC25U8RX_12E}
      sw-mappings:
        9 x swc to ecu mapping, all with ecu-instance=EcuInstance_explicitinter:
          SwcToEcuMapping_0: component=TopLevelComposition.CSWC1
          SwcToEcuMapping_1: component=TopLevelComposition.CSWC2
          SwcToEcuMapping_2: component=TopLevelComposition.CComM
          SwcToEcuMapping_3: component=TopLevelComposition
          SwcToEcuMapping_4: component=TopLevelComposition.CNvM
          SwcToEcuMapping_5: component=TopLevelComposition.CBswM
          SwcToEcuMapping_6: component=TopLevelComposition.SwComponentPrototype_explicitintrasend
          SwcToEcuMapping_7: component=TopLevelComposition.SwComponentPrototype_explicitintrareceive
          SwcToEcuMapping_8: component=TopLevelComposition.C_ExplicitInter
    root-software-compositions:
      root sw composition prototype TopLevelComposition: software-composition=CompositionSwComponentType_TopLevel
package /ArPackage_NMConfig
  nm config NmConfig_0
    can nm cluster CanNmCluster_0:
      communication-cluster=ComMChannel_CAN1
      nm-channel-id=0
      nm-channel-sleep-master=true
      nm-synchronizing-network=true
      nm-busload-reduction-active=false
      nm-car-wake-up-filter-enabled=false
      nm-car-wake-up-rx-enabled=false
      nm-channel-active=true
      nm-immediate-nm-cycle-time=0.02
      nm-immediate-nm-transmissions=1
      nm-message-timeout-time=0.01
      nm-msg-cycle-time=0.02
      nm-network-timeout=0.2
      nm-remote-sleep-indication-time=0.2
      nm-repeat-message-time=0.1
      nm-user-data-length=6
      nm-wait-bus-sleep-time=0.2
      can nm node CanNmNode_0: controller=CanCommunicationController_0, nm-if-ecu=NmEcu_0, nm-node-id=0, nm-passive-mode-enabled=false, rx-nm-pdu=NmPdu_RX, tx-nm-pdu=NmPdu_TX, nm-msg-cycle-offset=0.0, nm-msg-reduced-time=1.0
    nm-if-ecus:
      nm ecu NmEcu_0: ecu-instance=EcuInstance_explicitinter, nm-bus-synchronization-enabled=true, nm-com-control-enabled=false, nm-cycletime-main-function=0.01, nm-node-detection-enabled=false, nm-node-id-enabled=false, nm-passive-mode-enabled=false, nm-pdu-rx-indication-enabled=true, nm-remote-sleep-ind-enabled=true, nm-repeat-msg-ind-enabled=false, nm-state-change-ind-enabled=false, nm-user-data-enabled=false
package /ArPackage_Composition
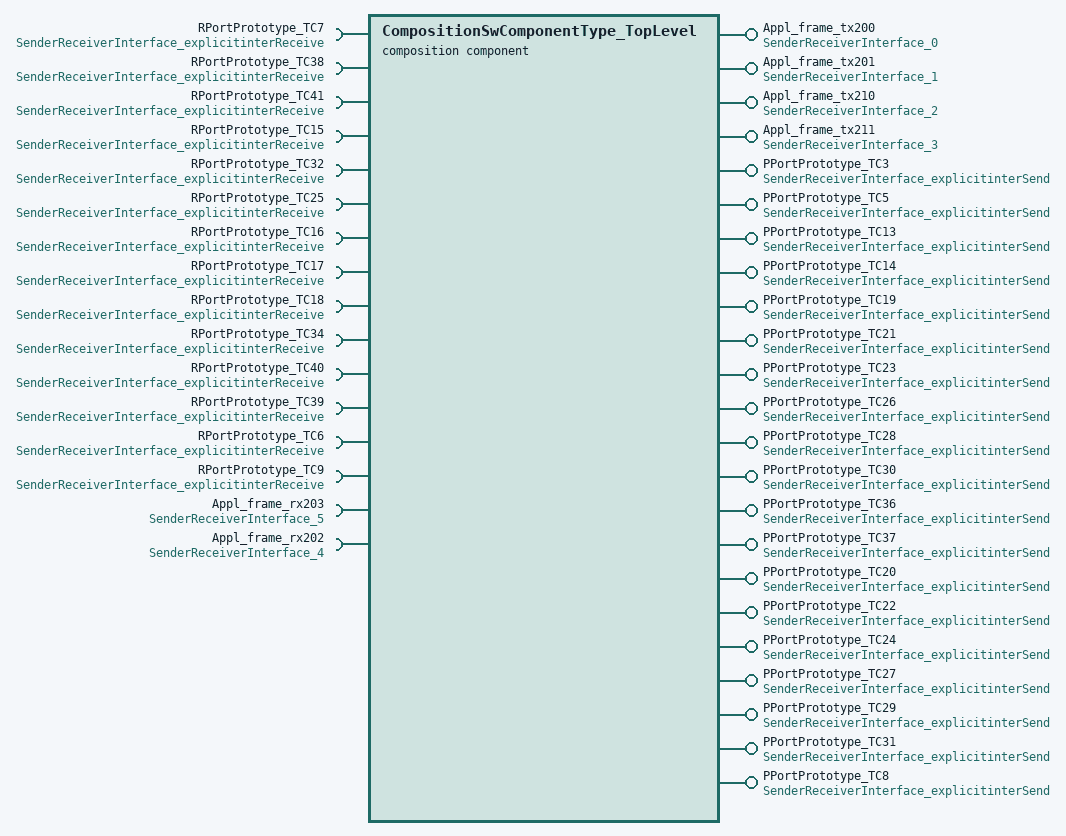
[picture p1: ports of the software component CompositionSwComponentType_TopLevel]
  composition sw component type CompositionSwComponentType_TopLevel
    23 x provide port:
      Appl_frame_tx200: nonqueued-sender-com-spec=init-value=EngObject:7, provided-interface=SenderReceiverInterface_0
      Appl_frame_tx201: nonqueued-sender-com-spec{data-element=SenderReceiverInterface_1/VariableDataPrototype_0, init-value=EngObject:8}, provided-interface=SenderReceiverInterface_1
      Appl_frame_tx210: nonqueued-sender-com-spec{data-element=SenderReceiverInterface_2/VariableDataPrototype_0, init-value=EngObject:9}, provided-interface=SenderReceiverInterface_2
      Appl_frame_tx211: nonqueued-sender-com-spec{data-element=SenderReceiverInterface_3/VariableDataPrototype_0, init-value=EngObject:10}, provided-interface=SenderReceiverInterface_3
      PPortPrototype_TC3: nonqueued-sender-com-spec{data-element=VariableDataPrototype_TC3, init-value=value:0}, provided-interface=SenderReceiverInterface_explicitinterSend
      PPortPrototype_TC5: nonqueued-sender-com-spec{data-element=VariableDataPrototype_TC5, init-value=5 x 1}, provided-interface=SenderReceiverInterface_explicitinterSend
      PPortPrototype_TC13: nonqueued-sender-com-spec{data-element=VariableDataPrototype_TC13, init-value=value:0}, provided-interface=SenderReceiverInterface_explicitinterSend
      PPortPrototype_TC14: nonqueued-sender-com-spec{data-element=VariableDataPrototype_TC14, init-value=5 x 1}, provided-interface=SenderReceiverInterface_explicitinterSend
      PPortPrototype_TC19: nonqueued-sender-com-spec{data-element=VariableDataPrototype_TC19, transmission-acknowledge=timeout=5.0, init-value=value:0}, provided-interface=SenderReceiverInterface_explicitinterSend
      PPortPrototype_TC21: nonqueued-sender-com-spec{data-element=VariableDataPrototype_TC21, transmission-acknowledge=timeout=7.0, init-value=value:0}, provided-interface=SenderReceiverInterface_explicitinterSend
      PPortPrototype_TC23: nonqueued-sender-com-spec{data-element=VariableDataPrototype_TC23, transmission-acknowledge=timeout=7.0, init-value=value:0}, provided-interface=SenderReceiverInterface_explicitinterSend
      PPortPrototype_TC26: nonqueued-sender-com-spec{data-element=VariableDataPrototype_TC26, transmission-acknowledge=timeout=7.0, init-value=5 x 1}, provided-interface=SenderReceiverInterface_explicitinterSend
      PPortPrototype_TC28: nonqueued-sender-com-spec{data-element=VariableDataPrototype_TC28, transmission-acknowledge=timeout=7.0, init-value=5 x 1}, provided-interface=SenderReceiverInterface_explicitinterSend
      PPortPrototype_TC30: nonqueued-sender-com-spec{data-element=VariableDataPrototype_TC30, transmission-acknowledge=timeout=7.0, init-value=value:0}, provided-interface=SenderReceiverInterface_explicitinterSend
      PPortPrototype_TC36: queued-sender-com-spec{data-element=VariableDataPrototype_TC36, transmission-acknowledge=timeout=7.0}, provided-interface=SenderReceiverInterface_explicitinterSend
      PPortPrototype_TC37: queued-sender-com-spec{data-element=VariableDataPrototype_TC37, transmission-acknowledge=timeout=7.0}, provided-interface=SenderReceiverInterface_explicitinterSend
      PPortPrototype_TC20: nonqueued-sender-com-spec{data-element=VariableDataPrototype_TC20, transmission-acknowledge=timeout=5.0, init-value=value:0}, provided-interface=SenderReceiverInterface_explicitinterSend
      PPortPrototype_TC22: nonqueued-sender-com-spec{data-element=VariableDataPrototype_TC22, transmission-acknowledge=timeout=5.0, init-value=value:0}, provided-interface=SenderReceiverInterface_explicitinterSend
      PPortPrototype_TC24: nonqueued-sender-com-spec{data-element=VariableDataPrototype_TC24, transmission-acknowledge=timeout=5.0, init-value=value:0}, provided-interface=SenderReceiverInterface_explicitinterSend
      PPortPrototype_TC27: nonqueued-sender-com-spec{data-element=VariableDataPrototype_TC27, transmission-acknowledge=timeout=5.0, init-value=5 x 1}, provided-interface=SenderReceiverInterface_explicitinterSend
      PPortPrototype_TC29: nonqueued-sender-com-spec{data-element=VariableDataPrototype_TC29, transmission-acknowledge=timeout=5.0, init-value=5 x 1}, provided-interface=SenderReceiverInterface_explicitinterSend
      PPortPrototype_TC31: nonqueued-sender-com-spec{data-element=VariableDataPrototype_TC31, transmission-acknowledge=timeout=5.0, init-value=5 x 1}, provided-interface=SenderReceiverInterface_explicitinterSend
      PPortPrototype_TC8: nonqueued-sender-com-spec{data-element=VariableDataPrototype_TC8, init-value=value:0}, provided-interface=SenderReceiverInterface_explicitinterSend
    16 x require port:
      RPortPrototype_TC7: nonqueued-receiver-com-spec{data-element=VariableDataPrototype_TC7, alive-timeout=0.005, init-value=5 x 1}, required-interface=SenderReceiverInterface_explicitinterReceive
      RPortPrototype_TC38: queued-receiver-com-spec{data-element=VariableDataPrototype_TC38, queue-length=3}, required-interface=SenderReceiverInterface_explicitinterReceive
      RPortPrototype_TC41: nonqueued-receiver-com-spec{data-element=VariableDataPrototype_TC41, alive-timeout=0.005, enable-update=true, init-value=value:0}, required-interface=SenderReceiverInterface_explicitinterReceive
      RPortPrototype_TC15: nonqueued-receiver-com-spec{data-element=VariableDataPrototype_TC15, alive-timeout=0.005, init-value=value:0}, required-interface=SenderReceiverInterface_explicitinterReceive
      RPortPrototype_TC32: nonqueued-receiver-com-spec{data-element=VariableDataPrototype_TC32, alive-timeout=0.01, init-value=value:0}, required-interface=SenderReceiverInterface_explicitinterReceive
      RPortPrototype_TC25: nonqueued-receiver-com-spec{data-element=VariableDataPrototype_TC25, alive-timeout=0.01, init-value=value:0}, required-interface=SenderReceiverInterface_explicitinterReceive
      RPortPrototype_TC16: nonqueued-receiver-com-spec{data-element=VariableDataPrototype_TC16, alive-timeout=0.005, init-value=value:0}, required-interface=SenderReceiverInterface_explicitinterReceive
      RPortPrototype_TC17: nonqueued-receiver-com-spec{data-element=VariableDataPrototype_TC17, alive-timeout=0.005, init-value=5 x 1}, required-interface=SenderReceiverInterface_explicitinterReceive
      RPortPrototype_TC18: nonqueued-receiver-com-spec{data-element=VariableDataPrototype_TC18, alive-timeout=0.005, init-value=5 x 1}, required-interface=SenderReceiverInterface_explicitinterReceive
      RPortPrototype_TC34: nonqueued-receiver-com-spec{data-element=VariableDataPrototype_TC34, alive-timeout=0.005, init-value=value:0}, required-interface=SenderReceiverInterface_explicitinterReceive
      RPortPrototype_TC40: queued-receiver-com-spec{data-element=VariableDataPrototype_TC40, queue-length=3}, required-interface=SenderReceiverInterface_explicitinterReceive
      RPortPrototype_TC39: queued-receiver-com-spec{data-element=VariableDataPrototype_TC39, queue-length=5}, required-interface=SenderReceiverInterface_explicitinterReceive
      RPortPrototype_TC6: nonqueued-receiver-com-spec{data-element=VariableDataPrototype_TC6, alive-timeout=0.005, init-value=value:0}, required-interface=SenderReceiverInterface_explicitinterReceive
      RPortPrototype_TC9: nonqueued-receiver-com-spec{data-element=VariableDataPrototype_TC9, alive-timeout=0.005, init-value=8 x 0}, required-interface=SenderReceiverInterface_explicitinterReceive
      Appl_frame_rx203: nonqueued-receiver-com-spec{data-element=SenderReceiverInterface_5/VariableDataPrototype_0, alive-timeout=0.005, init-value=value:3}, required-interface=SenderReceiverInterface_5
      Appl_frame_rx202: nonqueued-receiver-com-spec{data-element=SenderReceiverInterface_4/VariableDataPrototype_0, alive-timeout=0.005, init-value=value:3}, required-interface=SenderReceiverInterface_4
    10 x component:
      CSWC1: type=SWC1
      CSWC2: type=SWC2
      CComM
      CNvM: type=NvM
      CBswM
      SwComponentPrototype_explicitintrasend: type=ApplicationSwComponentType_ExplicitIntraSend
      SwComponentPrototype_explicitintrareceive: type=ApplicationSwComponentType_ExplicitIntraReceive
      C_ExplicitInter: type=ApplicationSwComponentType_ExplicitInter
      SwComponentPrototype_EcuM
      SwComponentPrototype_ComM
    connect CComM -> CSWC1.Client_UserRequest
    connect CComM -> CSWC2.Client_UserRequest
    connect CComM -> CSWC1.Client_CurrentMode
    connect CComM -> CSWC2.Client_CurrentMode
    connect CComM -> CSWC1.Client_CurrentChannelRequest
    connect CComM -> CSWC1.Client_ChannelLimitation
    connect CComM -> CSWC2.Client_ChannelLimitation
    connect CComM -> CSWC1.Client_ChannelWakeup
    connect CComM -> CSWC2.Client_ChannelWakeup
    connect CComM -> CSWC1.Client_ECUModeLimitation
    connect CComM -> CSWC2.Client_ECUModeLimitation
    connect CNvM.PS2 -> CSWC1.Client_NvMService2
    connect CNvM.PS3 -> CSWC1.Client_NvMService3
    connect CNvM.PAdmin2 -> CSWC1.Client_NvMAdmin
    connect CNvM.PS{4..7} -> CSWC1.Client_NvMService{4..7}
    connect CSWC1.BswMmodeRequestPort0 -> CBswM
    connect CComM -> CSWC2.Client_CurrentChannelRequest
    connect CSWC1.NvMNotifyJobFinished -> CNvM.PN3
    connect CSWC1.NvMNotifyJobFinished -> CNvM.PN2
    connect CSWC1.NvMNotifyInitBlock -> CNvM.PN{4..7}
    connect CSWC1.NvMMirror -> CNvM.PM2
    connect SwComponentPrototype_explicitintrasend.PPortPrototype_TC2 -> SwComponentPrototype_explicitintrareceive.RPortPrototype_TC2
    connect SwComponentPrototype_explicitintrasend.PPortPrototype_TC11 -> SwComponentPrototype_explicitintrareceive.RPortPrototype_TC11
    connect SwComponentPrototype_explicitintrasend.PPortPrototype_TC12 -> SwComponentPrototype_explicitintrareceive.RPortPrototype_TC12
    connect SwComponentPrototype_explicitintrasend.PPortPrototype_TC33 -> SwComponentPrototype_explicitintrareceive.RPortPrototype_TC33
    connect SwComponentPrototype_explicitintrasend.PPortPrototype_TC35 -> SwComponentPrototype_explicitintrareceive.RPortPrototype_TC35
    connect SwComponentPrototype_explicitintrasend.PPortPrototype_TC42 -> SwComponentPrototype_explicitintrareceive.RPortPrototype_TC42
    connect SwComponentPrototype_explicitintrasend.PPortPrototype_TC10 -> SwComponentPrototype_explicitintrareceive.RPortPrototype_TC10
    delegate CSWC1.Appl_frame_rx202 <-> outer port CompositionSwComponentType_TopLevel/Appl_frame_rx202
    delegate CSWC1.Appl_frame_rx203 <-> outer port CompositionSwComponentType_TopLevel/Appl_frame_rx203
    delegate CSWC1.Appl_frame_tx200 <-> outer port CompositionSwComponentType_TopLevel/Appl_frame_tx200
    delegate CSWC1.Appl_frame_tx201 <-> outer port CompositionSwComponentType_TopLevel/Appl_frame_tx201
    delegate CSWC1.Appl_frame_tx210 <-> outer port CompositionSwComponentType_TopLevel/Appl_frame_tx210
    delegate CSWC1.Appl_frame_tx211 <-> outer port CompositionSwComponentType_TopLevel/Appl_frame_tx211
    delegate C_ExplicitInter.RPortPrototype_TC7 <-> outer port CompositionSwComponentType_TopLevel/RPortPrototype_TC7
    delegate C_ExplicitInter.RPortPrototype_TC38 <-> outer port CompositionSwComponentType_TopLevel/RPortPrototype_TC38
    delegate C_ExplicitInter.RPortPrototype_TC41 <-> outer port CompositionSwComponentType_TopLevel/RPortPrototype_TC41
    delegate C_ExplicitInter.RPortPrototype_TC15 <-> outer port CompositionSwComponentType_TopLevel/RPortPrototype_TC15
    delegate C_ExplicitInter.RPortPrototype_TC32 <-> outer port CompositionSwComponentType_TopLevel/RPortPrototype_TC32
    delegate C_ExplicitInter.RPortPrototype_TC25 <-> outer port CompositionSwComponentType_TopLevel/RPortPrototype_TC25
    delegate C_ExplicitInter.RPortPrototype_TC{16..18} <-> outer port CompositionSwComponentType_TopLevel/RPortPrototype_TC{16..18}
    delegate C_ExplicitInter.RPortPrototype_TC34 <-> outer port CompositionSwComponentType_TopLevel/RPortPrototype_TC34
    delegate C_ExplicitInter.RPortPrototype_TC40 <-> outer port CompositionSwComponentType_TopLevel/RPortPrototype_TC40
    delegate C_ExplicitInter.RPortPrototype_TC39 <-> outer port CompositionSwComponentType_TopLevel/RPortPrototype_TC39
    delegate C_ExplicitInter.RPortPrototype_TC6 <-> outer port CompositionSwComponentType_TopLevel/RPortPrototype_TC6
    delegate C_ExplicitInter.RPortPrototype_TC9 <-> outer port CompositionSwComponentType_TopLevel/RPortPrototype_TC9
    delegate C_ExplicitInter.PPortPrototype_TC3 <-> outer port CompositionSwComponentType_TopLevel/PPortPrototype_TC3
    delegate C_ExplicitInter.PPortPrototype_TC5 <-> outer port CompositionSwComponentType_TopLevel/PPortPrototype_TC5
    delegate C_ExplicitInter.PPortPrototype_TC13 <-> outer port CompositionSwComponentType_TopLevel/PPortPrototype_TC13
    delegate C_ExplicitInter.PPortPrototype_TC14 <-> outer port CompositionSwComponentType_TopLevel/PPortPrototype_TC14
    delegate C_ExplicitInter.PPortPrototype_TC19 <-> outer port CompositionSwComponentType_TopLevel/PPortPrototype_TC19
    delegate C_ExplicitInter.PPortPrototype_TC21 <-> outer port CompositionSwComponentType_TopLevel/PPortPrototype_TC21
    delegate C_ExplicitInter.PPortPrototype_TC23 <-> outer port CompositionSwComponentType_TopLevel/PPortPrototype_TC23
    delegate C_ExplicitInter.PPortPrototype_TC26 <-> outer port CompositionSwComponentType_TopLevel/PPortPrototype_TC26
    delegate C_ExplicitInter.PPortPrototype_TC28 <-> outer port CompositionSwComponentType_TopLevel/PPortPrototype_TC28
    delegate C_ExplicitInter.PPortPrototype_TC30 <-> outer port CompositionSwComponentType_TopLevel/PPortPrototype_TC30
    delegate C_ExplicitInter.PPortPrototype_TC36 <-> outer port CompositionSwComponentType_TopLevel/PPortPrototype_TC36
    delegate C_ExplicitInter.PPortPrototype_TC37 <-> outer port CompositionSwComponentType_TopLevel/PPortPrototype_TC37
    delegate C_ExplicitInter.PPortPrototype_TC20 <-> outer port CompositionSwComponentType_TopLevel/PPortPrototype_TC20
    delegate C_ExplicitInter.PPortPrototype_TC22 <-> outer port CompositionSwComponentType_TopLevel/PPortPrototype_TC22
    delegate C_ExplicitInter.PPortPrototype_TC24 <-> outer port CompositionSwComponentType_TopLevel/PPortPrototype_TC24
    delegate C_ExplicitInter.PPortPrototype_TC27 <-> outer port CompositionSwComponentType_TopLevel/PPortPrototype_TC27
    delegate C_ExplicitInter.PPortPrototype_TC29 <-> outer port CompositionSwComponentType_TopLevel/PPortPrototype_TC29
    delegate C_ExplicitInter.PPortPrototype_TC31 <-> outer port CompositionSwComponentType_TopLevel/PPortPrototype_TC31
    delegate C_ExplicitInter.PPortPrototype_TC8 <-> outer port CompositionSwComponentType_TopLevel/PPortPrototype_TC8
    connect SwComponentPrototype_EcuM -> CSWC1.Client_ShutdownTarget
    connect SwComponentPrototype_EcuM -> CSWC1.Client_BootTarget
    connect SwComponentPrototype_ComM -> CSWC1.Client_ChannelLimitation
    connect SwComponentPrototype_ComM -> CSWC2.Client_ChannelLimitation
    connect SwComponentPrototype_ComM -> CSWC1.Client_ECUModeLimitation
    connect SwComponentPrototype_ComM -> CSWC2.Client_ECUModeLimitation
    connect SwComponentPrototype_ComM -> CSWC1.Client_ChannelWakeup
    connect SwComponentPrototype_ComM -> CSWC1.Client_CurrentMode
    connect SwComponentPrototype_ComM -> CSWC2.Client_CurrentMode
    connect SwComponentPrototype_ComM -> CSWC1.Client_UserRequest
    connect SwComponentPrototype_ComM -> CSWC2.Client_UserRequest
    connect SwComponentPrototype_ComM -> CSWC2.Client_ChannelWakeup
package /ArPackage_EcuM
  impl type EcuM_StateType: category=VALUE, base-type=uint8_base
  client server interface EcuM_ShutdownTarget: is-service=true, service-kind=ECU-MANAGER
    7 x operation:
      SelectShutdownTarget
        arg ArgumentDataPrototype_0: type=EcuM_StateType, direction=IN
        arg ArgumentDataPrototype_1: type=EcuM_UserType, direction=IN
      GetShutdownTarget
        arg ArgumentDataPrototype_0: type=EcuM_StateType, direction=OUT
        arg ArgumentDataPrototype_1: type=EcuM_UserType, direction=OUT
      GetLastShutdownTarget
        arg ArgumentDataPrototype_0: type=EcuM_StateType, direction=OUT
        arg ArgumentDataPrototype_1: type=EcuM_UserType, direction=OUT
      SelectShutdownCause
        arg ArgumentDataPrototype_0: type=EcuM_ShutdownCauseType, direction=IN
      GetShutdownCause
        arg ArgumentDataPrototype_0: type=EcuM_ShutdownCauseType, direction=OUT
      GetMostRecentShutdown
        4 x arg, all with direction=OUT:
          ArgumentDataPrototype_0: type=EcuM_StateType
          ArgumentDataPrototype_1: type=EcuM_UserType
          ArgumentDataPrototype_2: type=EcuM_ShutdownCauseType
          ArgumentDataPrototype_3: type=EcuM_TimeType
      GetNextRecentShutdown
        4 x arg, all with direction=OUT:
          ArgumentDataPrototype_0: type=EcuM_StateType
          ArgumentDataPrototype_1: type=EcuM_UserType
          ArgumentDataPrototype_2: type=EcuM_ShutdownCauseType
          ArgumentDataPrototype_3: type=EcuM_TimeType
    error E_NOT_OK: error-code=1
  impl type EcuM_UserType: category=VALUE, base-type=uint8_base
  impl type EcuM_ShutdownCauseType: category=VALUE, base-type=uint8_base
  impl type EcuM_TimeType: category=VALUE, base-type=uint32_base
  client server interface EcuM_BootTarget: is-service=true, service-kind=ECU-MANAGER
    operation SelectBootTarget
      arg ArgumentDataPrototype_0: type=EcuM_BootTargetType, direction=IN
    operation GetBootTarget
      arg ArgumentDataPrototype_0: type=EcuM_BootTargetType, direction=OUT
    error E_NOT_OK: error-code=1
  impl type EcuM_BootTargetType: category=VALUE, base-type=uint8_base
  client server interface EcuM_AlarmClock: service-kind=ECU-MANAGER
    6 x operation:
      SetRelWakeupAlarm
        arg ArgumentDataPrototype_1: type=EcuM_TimeType, direction=IN
      SetAbsWakeupAlarm
        arg ArgumentDataPrototype_1: type=EcuM_TimeType, direction=IN
      AbortWakeupAlarm
      GetCurrentTime
        arg ArgumentDataPrototype_0: type=EcuM_TimeType, direction=OUT
      GetWakeupTime
        arg ArgumentDataPrototype_0: type=EcuM_TimeType, direction=OUT
      SetClock
        arg ArgumentDataPrototype_0: type=EcuM_TimeType, direction=IN
    5 x error:
      E_NOT_OK: error-code=1
      E_NOT_SUPPORTED: error-code=2
      E_EARLIER_ACTIVE: error-code=3
      E_PAST: error-code=4
      E_NOT_ALLOWED: error-code=6
package /ArPackage_SWC
  base type uint8_base: category=FIXED_LENGTH, base-type-size=8, base-type-encoding=NONE, native-declaration=unsigned char
  base type boolean_base: category=FIXED_LENGTH, base-type-size=8, base-type-encoding=NONE, native-declaration=unsigned char
  sender receiver interface SenderReceiverInterface_0
    data VariableDataPrototype_0: type=ArPackage_SWC/uint8
  sender receiver interface SenderReceiverInterface_1
    data VariableDataPrototype_0: type=ArPackage_SWC/uint8
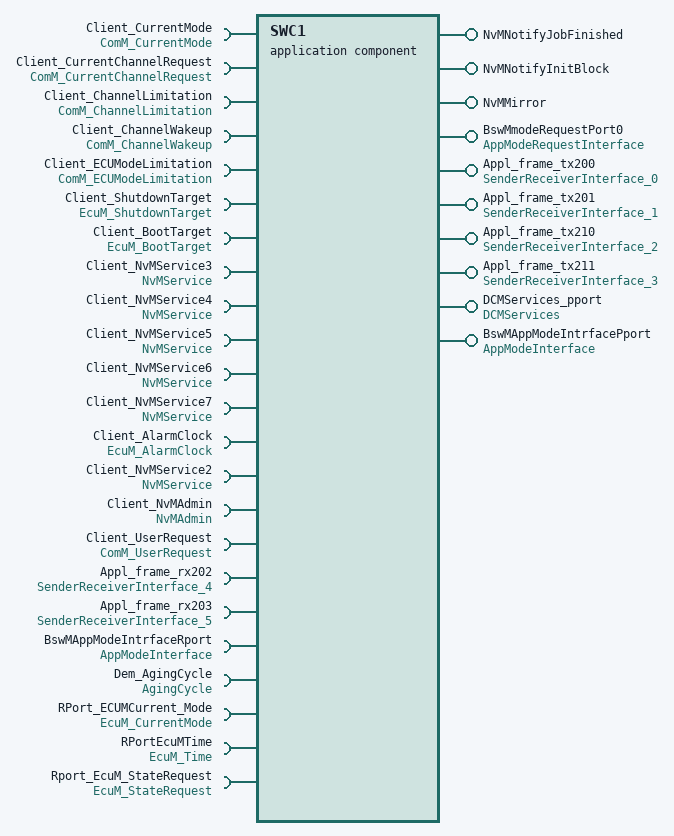
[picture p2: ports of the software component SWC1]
  application sw component type SWC1
    8 x provide port:
      NvMNotifyJobFinished: server-com-spec{operation=JobFinished, queue-length=1}, provided-interface=NvMNotifyJobFinished
      NvMNotifyInitBlock: server-com-spec=queue-length=1, provided-interface=NvMNotifyInitBlock
      NvMMirror: provided-com-specs=[{operation=ReadRamBlockFromNvm, queue-length=1}, {operation=WriteRamBlockToNvm, queue-length=1}], provided-interface=NvMMirror
      BswMmodeRequestPort0: nonqueued-sender-com-spec{data-element=requestedMode, init-value=EngObject:5}, provided-interface=AppModeRequestInterface
      Appl_frame_tx200: nonqueued-sender-com-spec{data-element=SenderReceiverInterface_0/VariableDataPrototype_0, init-value=EngObject:7}, provided-interface=SenderReceiverInterface_0
      Appl_frame_tx201: nonqueued-sender-com-spec{data-element=SenderReceiverInterface_1/VariableDataPrototype_0, init-value=EngObject:8}, provided-interface=SenderReceiverInterface_1
      Appl_frame_tx210: nonqueued-sender-com-spec=init-value=EngObject:9, provided-interface=SenderReceiverInterface_2
      Appl_frame_tx211: nonqueued-sender-com-spec=init-value=EngObject:10, provided-interface=SenderReceiverInterface_3
    20 x require port:
      Client_CurrentMode: required-interface=ComM_CurrentMode
      Client_CurrentChannelRequest: nonqueued-receiver-com-spec{data-element=fullComRequestors, init-value={short-label=EngObj, fields=[engobj:0, EngObj:[EngObj:0, EngObj:0]]}}, required-interface=ComM_CurrentChannelRequest
      Client_ChannelLimitation: required-com-specs=[LimitChannelToNoComMode, GetInhibitionStatus], required-interface=ComM_ChannelLimitation
      Client_ChannelWakeup: client-com-spec=PreventWakeUp, required-interface=ComM_ChannelWakeup
      Client_ECUModeLimitation: required-com-specs=[LimitECUToNoComMode, ReadInhibitCounter, ResetInhibitCounter, SetECUGroupClassification], required-interface=ComM_ECUModeLimitation
      Client_ShutdownTarget: required-interface=EcuM_ShutdownTarget
        required-com-specs:
          SelectShutdownTarget
          GetShutdownTarget
          GetLastShutdownTarget
          SelectShutdownCause
          SelectShutdownCause
          GetMostRecentShutdown
          GetNextRecentShutdown
      Client_BootTarget: required-com-specs=[SelectBootTarget, GetBootTarget], required-interface=EcuM_BootTarget
      Client_NvMService3: required-interface=NvMService
        required-com-specs:
          GetErrorStatus
          SetDataIndex
          GetDataIndex
          SetRamBlockStatus
          ReadBlock
          WriteBlock
          RestoreBlockDefaults
          EraseBlock
          InvalidateNvBlock
      Client_NvMService4: required-interface=NvMService
        required-com-specs:
          GetErrorStatus
          SetDataIndex
          GetDataIndex
          SetRamBlockStatus
          ReadBlock
          WriteBlock
          RestoreBlockDefaults
          EraseBlock
          InvalidateNvBlock
          CancelJobs
      Client_NvMService5: required-interface=NvMService
        required-com-specs:
          GetErrorStatus
          SetDataIndex
          GetDataIndex
          SetRamBlockStatus
          ReadBlock
          WriteBlock
          RestoreBlockDefaults
          EraseBlock
          InvalidateNvBlock
          CancelJobs
      Client_NvMService6: required-interface=NvMService
        required-com-specs:
          GetErrorStatus
          SetDataIndex
          GetDataIndex
          SetRamBlockStatus
          ReadBlock
          WriteBlock
          RestoreBlockDefaults
          EraseBlock
          InvalidateNvBlock
          CancelJobs
      Client_NvMService7: required-interface=NvMService
        required-com-specs:
          GetErrorStatus
          SetDataIndex
          GetDataIndex
          SetRamBlockStatus
          ReadBlock
          WriteBlock
          RestoreBlockDefaults
          EraseBlock
          InvalidateNvBlock
          CancelJobs
      Client_AlarmClock: required-interface=EcuM_AlarmClock
        required-com-specs:
          SetRelWakeupAlarm
          SetAbsWakeupAlarm
          AbortWakeupAlarm
          EcuM_AlarmClock/GetCurrentTime
          GetWakeupTime
          SetClock
      Client_NvMService2: required-interface=NvMService
        required-com-specs:
          GetErrorStatus
          SetDataIndex
          GetDataIndex
          SetRamBlockStatus
          ReadBlock
          WriteBlock
          RestoreBlockDefaults
          EraseBlock
          InvalidateNvBlock
      Client_NvMAdmin: client-com-spec=SetBlockProtection, required-interface=NvMAdmin
      Client_UserRequest: required-com-specs=[RequestComMode, GetCurrentComMode, GetRequestedComMode, GetMaxComMode], required-interface=ComM_UserRequest
      Appl_frame_rx202: nonqueued-receiver-com-spec{alive-timeout=0.005, init-value=value:3}, required-interface=SenderReceiverInterface_4
      Appl_frame_rx203: nonqueued-receiver-com-spec{alive-timeout=0.005, init-value=value:3}, required-interface=SenderReceiverInterface_5
      BswMAppModeIntrfaceRport: required-interface=AppModeInterface
      Dem_AgingCycle: required-interface=AgingCycle
    provide port DCMServices_pport: provided-interface=DCMServices
    require port RPort_ECUMCurrent_Mode: required-interface=EcuM_CurrentMode
    require port RPortEcuMTime: required-interface=EcuM_Time
    provide port BswMAppModeIntrfacePport: provided-interface=AppModeInterface
    require port Rport_EcuM_StateRequest: required-interface=EcuM_StateRequest
    behavior IB_SWC1: data-type-mapping=[DataTypeMappingSet_1, ArPackage_ComM/DataTypeMappingSet_0], handle-termination-and-restart=CAN-BE-TERMINATED-AND-RESTARTED
      swc mode switch event SwcModeSwitchEvent_1: start-on-event=SWC1_ComM_ModeswitchRunnable, activation=ON-ENTRY, mode=Client_CurrentMode.COMM_FULL_COMMUNICATION
      swc mode switch event SwcModeSwitchEvent_0: start-on-event=SWC1_ComM_ModeswitchRunnable, activation=ON-ENTRY, mode=Client_CurrentMode.currentMode.COMM_NO_COMMUNICATION
      5 x timing event:
        TimingEvent_BswM: start-on-event=SWC1_BswM_Runnable1, period=0.005
        TimingEvent_EcuM: start-on-event=SWC1_EcuM_Runnable1, period=0.005
        TimingEvent_Appl_frame: start-on-event=SWC1_Appl_frame, period=0.01
        TimingEvent_ComM: start-on-event=SWC1_ComM_Runnable1, period=0.005
        TimingEvent_NvM: start-on-event=SWC1_NvM_Runnable1, period=0.005
      6 x runnable:
        SWC1_EcuM_Runnable1
          15 x sync call, all with timeout=0.0:
            SynchronousServerCallPoint_0: operation=Client_ShutdownTarget.SelectShutdownTarget
            SynchronousServerCallPoint_1: operation=Client_ShutdownTarget.GetShutdownTarget
            SynchronousServerCallPoint_2: operation=Client_ShutdownTarget.GetLastShutdownTarget
            SynchronousServerCallPoint_3: operation=Client_ShutdownTarget.SelectShutdownCause
            SynchronousServerCallPoint_4: operation=Client_ShutdownTarget.GetShutdownCause
            SynchronousServerCallPoint_5: operation=Client_ShutdownTarget.GetMostRecentShutdown
            SynchronousServerCallPoint_6: operation=Client_ShutdownTarget.GetNextRecentShutdown
            SynchronousServerCallPoint_7: operation=Client_BootTarget.SelectBootTarget
            SynchronousServerCallPoint_8: operation=Client_BootTarget.GetBootTarget
            SynchronousServerCallPoint_9: operation=Client_AlarmClock.SetRelWakeupAlarm
            SynchronousServerCallPoint_10: operation=Client_AlarmClock.SetAbsWakeupAlarm
            SynchronousServerCallPoint_11: operation=Client_AlarmClock.AbortWakeupAlarm
            SynchronousServerCallPoint_12: operation=Client_AlarmClock.GetCurrentTime
            SynchronousServerCallPoint_13: operation=Client_AlarmClock.GetWakeupTime
            SynchronousServerCallPoint_14: operation=Client_AlarmClock.SetClock
        SWC1_ComM_Runnable1
          data-receive-point-by-arguments:
            access VariableAccess_0: accessed-variable={autosar-variable=Client_CurrentChannelRequest.fullComRequestors.fullComRequestors, local-variable=fullComRequestors}
          11 x sync call, all with timeout=0.0:
            SynchronousServerCallPoint_0: operation=Client_UserRequest.RequestComMode
            SynchronousServerCallPoint_1: operation=Client_UserRequest.GetCurrentComMode
            SynchronousServerCallPoint_2: operation=Client_UserRequest.GetMaxComMode
            SynchronousServerCallPoint_3: operation=Client_UserRequest.GetRequestedComMode
            SynchronousServerCallPoint_4: operation=Client_ECUModeLimitation.LimitECUToNoComMode
            SynchronousServerCallPoint_5: operation=Client_ECUModeLimitation.ReadInhibitCounter
            SynchronousServerCallPoint_6: operation=Client_ECUModeLimitation.ResetInhibitCounter
            SynchronousServerCallPoint_7: operation=Client_ECUModeLimitation.SetECUGroupClassification
            SynchronousServerCallPoint_8: operation=Client_ChannelWakeup.PreventWakeUp
            SynchronousServerCallPoint_9: operation=Client_ChannelLimitation.LimitChannelToNoComMode
            SynchronousServerCallPoint_10: operation=Client_ChannelLimitation.GetInhibitionStatus
        SWC1_NvM_Runnable1
          5 x async call, all with timeout=0.0:
            AsynchronousServerCallPoint_0: operation=Client_NvMService2.ReadBlock
            AsynchronousServerCallPoint_1: operation=Client_NvMService2.WriteBlock
            AsynchronousServerCallPoint_2: operation=Client_NvMService2.RestoreBlockDefaults
            AsynchronousServerCallPoint_3: operation=Client_NvMService2.EraseBlock
            AsynchronousServerCallPoint_4: operation=Client_NvMService2.InvalidateNvBlock
          5 x sync call, all with timeout=0.0:
            SynchronousServerCallPoint_1: operation=Client_NvMService2.SetDataIndex
            SynchronousServerCallPoint_2: operation=Client_NvMService2.GetDataIndex
            SynchronousServerCallPoint_3: operation=Client_NvMService2.SetRamBlockStatus
            SynchronousServerCallPoint_0: operation=Client_NvMService2.GetErrorStatus
            SynchronousServerCallPoint_4: operation=Client_NvMAdmin.SetBlockProtection
        SWC1_BswM_Runnable1: minimum-start-interval=0.005
          data-write-access:
            access VariableAccess_0: accessed-variable={autosar-variable=BswMmodeRequestPort0.requestedMode.requestedMode, local-variable=requestedMode}
        SWC1_Appl_frame: minimum-start-interval=0.005, symbol=SWC1_Appl_Runnable1
          data-receive-point-by-arguments:
            access VariableAccess_0: accessed-variable=Appl_frame_rx202.VariableDataPrototype_0
            access VariableAccess_1: accessed-variable=Appl_frame_rx203.VariableDataPrototype_0
          data-send-points:
            4 x access:
              VariableAccess_2: accessed-variable=Appl_frame_tx200.VariableDataPrototype_0
              VariableAccess_3: accessed-variable=Appl_frame_tx201.VariableDataPrototype_0
              VariableAccess_4: accessed-variable=Appl_frame_tx210.VariableDataPrototype_0
              VariableAccess_5: accessed-variable=Appl_frame_tx211.VariableDataPrototype_0
        SWC1_ComM_ModeswitchRunnable
      4 x swc service dependency:
        BswMDependency
          assigned-ports:
            port-prototype=BswMAppModeIntrfaceRport, role=AppModeInterface
            port-prototype=BswMmodeRequestPort0, role=AppModeRequestInterface
            port-prototype=BswMAppModeIntrfacePport, role=AppModeInterface
          service-needs:
            bsw mgr needs BswMgrNeeds
        EcuMServiceDependency
          assigned-ports:
            port-prototype=Client_BootTarget, role=EcuM_BootTarget
            port-prototype=Client_AlarmClock, role=EcuM_AlarmClock
            port-prototype=Client_ShutdownTarget, role=EcuM_ShutdownTarget
            port-prototype=RPort_ECUMCurrent_Mode, role=EcuM_CurrentMode
            port-prototype=RPortEcuMTime, role=EcuM_Time
            port-prototype=Rport_EcuM_StateRequest, role=EcuM_StateRequest
          service-needs:
            ecu state mgr user needs EcuMgrNeeds
        DeMServiceDependency: assigned-ports=role-based-port-assignment={port-prototype=Dem_AgingCycle, role=AgingCycle}
        DcmDependency: assigned-ports=role-based-port-assignment={port-prototype=DCMServices_pport, role=DCMServices}
          service-needs:
            diagnostic communication manager needs dcmserviceneed
  base type uint32_base: category=FIXED_LENGTH, base-type-size=32, base-type-encoding=NONE, native-declaration=unsigned long
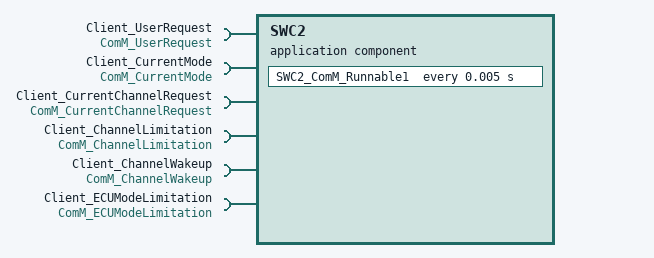
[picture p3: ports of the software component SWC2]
  application sw component type SWC2
    6 x require port:
      Client_UserRequest: required-com-specs=[RequestComMode, GetCurrentComMode, GetRequestedComMode, GetMaxComMode], required-interface=ComM_UserRequest
      Client_CurrentMode: required-interface=ComM_CurrentMode
      Client_CurrentChannelRequest: nonqueued-receiver-com-spec{alive-timeout=0.005, init-value={short-label=EngObj, fields=[engobj:0, EngObj:[EngObj:0, EngObj:0]]}}, required-interface=ComM_CurrentChannelRequest
      Client_ChannelLimitation: required-com-specs=[LimitChannelToNoComMode, GetInhibitionStatus], required-interface=ComM_ChannelLimitation
      Client_ChannelWakeup: client-com-spec=PreventWakeUp, required-interface=ComM_ChannelWakeup
      Client_ECUModeLimitation: required-com-specs=[LimitECUToNoComMode, ReadInhibitCounter, ResetInhibitCounter, SetECUGroupClassification], required-interface=ComM_ECUModeLimitation
    behavior IB_SWC2: data-type-mapping=ArPackage_ComM/DataTypeMappingSet_0, handle-termination-and-restart=CAN-BE-TERMINATED-AND-RESTARTED
      timing event TimingEvent_ComM2: start-on-event=SWC2_ComM_Runnable1, period=0.005
      runnable SWC2_ComM_Runnable1: minimum-start-interval=0.005
        data-receive-point-by-arguments:
          access VariableAccess_0: accessed-variable={autosar-variable=Client_CurrentChannelRequest.fullComRequestors.fullComRequestors, local-variable=fullComRequestors}
        sync call SynchronousServerCallPoint_0: operation=Client_UserRequest.RequestComMode, timeout=0.0
        sync call SynchronousServerCallPoint_1: operation=Client_UserRequest.GetCurrentComMode, timeout=0.0
      4 x swc service dependency:
        SD_Chnwkup: assigned-ports=role-based-port-assignment={port-prototype=SWC2/Client_ChannelWakeup, role=ComM_ChannelWakeup}
          service-needs:
            com mgr user needs ChnWhupNeeds
        SDChannelLmt
          assigned-ports:
            port-prototype=SWC2/Client_ChannelLimitation, role=ComM_ChannelLimitation
            port-prototype=SWC2/Client_ECUModeLimitation, role=ComM_ECUModeLimitation
          service-needs:
            com mgr user needs ChnLmtNeeds
        SDCurrentMode: assigned-ports=role-based-port-assignment={port-prototype=SWC2/Client_CurrentMode, role=ComM_CurrentMode}
          service-needs:
            com mgr user needs CurrentModeNeeds
        SD_ComM_UserRequest: assigned-ports=role-based-port-assignment={port-prototype=SWC2/Client_UserRequest, role=ComM_UserRequest}
          service-needs:
            com mgr user needs ComMNeeds
  base type uint16_base: category=FIXED_LENGTH, base-type-size=16, base-type-encoding=NONE, native-declaration=unsigned short
  sender receiver interface SenderReceiverInterface_4
    data VariableDataPrototype_0: type=ArPackage_SWC/uint8
  sender receiver interface SenderReceiverInterface_5
    data VariableDataPrototype_0: type=ArPackage_SWC/uint8
  sender receiver interface SenderReceiverInterface_2
    data VariableDataPrototype_0: type=ArPackage_SWC/uint8
  sender receiver interface SenderReceiverInterface_3
    data VariableDataPrototype_0: type=ArPackage_SWC/uint8
  client server interface AgingCycle: is-service=true
  client server interface DCMServices
  mode switch interface EcuM_CurrentMode: is-service=true
    mode group currentMode
  client server interface EcuM_Time: service-kind=BASIC-SOFTWARE-MODE-MANAGER
    operation GetCurrentTime
      arg time: direction=OUT
  mode switch interface AppModeInterface
  client server interface EcuM_StateRequest
    operation ReleasePOSTRUN
    operation ReleaseRUN
package /ArPackage_Explicit_Intra
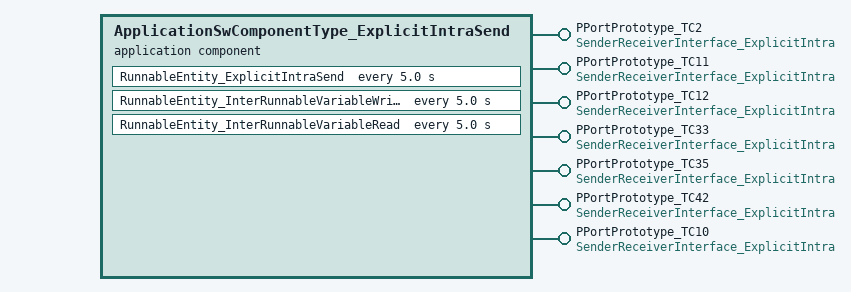
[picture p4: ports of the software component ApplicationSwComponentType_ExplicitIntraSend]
  application sw component type ApplicationSwComponentType_ExplicitIntraSend
    7 x provide port, all with provided-interface=SenderReceiverInterface_ExplicitIntra:
      PPortPrototype_TC2: nonqueued-sender-com-spec=init-value=0
      PPortPrototype_TC11: nonqueued-sender-com-spec{data-element=VariableDataPrototype_TC11, init-value=170}
      PPortPrototype_TC12: nonqueued-sender-com-spec{data-element=VariableDataPrototype_TC12, init-value=5}
      PPortPrototype_TC33: nonqueued-sender-com-spec{data-element=VariableDataPrototype_TC33, init-value=0}
      PPortPrototype_TC35: queued-sender-com-spec=data-element=VariableDataPrototype_TC35
      PPortPrototype_TC42: nonqueued-sender-com-spec{data-element=VariableDataPrototype_TC42, init-value=0}
      PPortPrototype_TC10: nonqueued-sender-com-spec{data-element=VariableDataPrototype_TC10, init-value=0}
    behavior SwcInternalBehavior_ExplicitIntra: handle-termination-and-restart=CAN-BE-TERMINATED-AND-RESTARTED
      timing event TimingEvent_RunnableEntity_ExplicitIntraSend: start-on-event=RunnableEntity_ExplicitIntraSend, period=5.0
      timing event TimingEvent_InterRunnableVariableWrite: start-on-event=RunnableEntity_InterRunnableVariableWrite, period=5.0
      timing event TimingEvent_InterRunnableVariableRead: start-on-event=RunnableEntity_InterRunnableVariableRead, period=5.0
      explicit-inter-runnable-variables:
        data VariableDataPrototype_TC59: type=uint8_ExpIntra, init-value=engobj:0
      implicit-inter-runnable-variables:
        data VariableDataPrototype_TC60: type=uint8_ExpIntra, init-value=engobj:0
      runnable RunnableEntity_ExplicitIntraSend
        data-send-points:
          7 x access:
            VariableAccess_TC2: accessed-variable={autosar-variable=PPortPrototype_TC2.VariableDataPrototype_TC2, local-variable=VariableDataPrototype_TC2}
            VariableAccess_TC11: accessed-variable={autosar-variable=PPortPrototype_TC11.VariableDataPrototype_TC11, local-variable=VariableDataPrototype_TC11}
            VariableAccess_TC12: accessed-variable={autosar-variable=PPortPrototype_TC12.VariableDataPrototype_TC12, local-variable=VariableDataPrototype_TC12}
            VariableAccess_TC33: accessed-variable={autosar-variable=PPortPrototype_TC33.VariableDataPrototype_TC33, local-variable=VariableDataPrototype_TC33}
            VariableAccess_TC35: accessed-variable={autosar-variable=PPortPrototype_TC35.VariableDataPrototype_TC35, local-variable=VariableDataPrototype_TC35}
            VariableAccess_TC42: accessed-variable={autosar-variable=PPortPrototype_TC42.VariableDataPrototype_TC42, local-variable=VariableDataPrototype_TC42}
            VariableAccess_TC10: accessed-variable={autosar-variable=PPortPrototype_TC10.VariableDataPrototype_TC10, local-variable=VariableDataPrototype_TC10}
      runnable RunnableEntity_InterRunnableVariableWrite
        written-local-variables:
          access VariableAccess_TC59: accessed-variable=VariableDataPrototype_TC59
          access VariableAccess_TC60: accessed-variable=VariableDataPrototype_TC60
      runnable RunnableEntity_InterRunnableVariableRead
        read-local-variables:
          access VariableAccess_TC59: accessed-variable=VariableDataPrototype_TC59
          access VariableAccess_TC60: accessed-variable=VariableDataPrototype_TC60
  sender receiver interface SenderReceiverInterface_ExplicitIntra
    7 x data:
      VariableDataPrototype_TC2: type=uint8_ExpIntra
      VariableDataPrototype_TC11: type=uint8_ExpIntra, init-value=170
      VariableDataPrototype_TC12: type=uint8_ExpIntra, init-value=5
      VariableDataPrototype_TC10: type=uint8_ExpIntra, init-value=170
      VariableDataPrototype_TC33: type=uint8_ExpIntra
      VariableDataPrototype_TC35: type=uint8_queued
      VariableDataPrototype_TC42: type=uint8_ExpIntra
    invalidation-policys:
      data-element=VariableDataPrototype_TC11, handle-invalid=KEEP
      data-element=VariableDataPrototype_TC12, handle-invalid=REPLACE
      data-element=VariableDataPrototype_TC10, handle-invalid=KEEP
  impl type uint8_ExpIntra: category=VALUE, base-type=uint8_base, invalid-value=170, sw-is-virtual=false
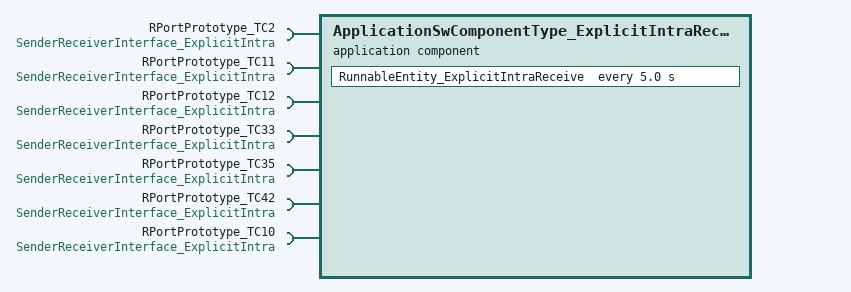
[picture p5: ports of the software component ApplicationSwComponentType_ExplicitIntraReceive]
  application sw component type ApplicationSwComponentType_ExplicitIntraReceive
    7 x require port, all with required-interface=SenderReceiverInterface_ExplicitIntra:
      RPortPrototype_TC2: nonqueued-receiver-com-spec{data-element=VariableDataPrototype_TC2, alive-timeout=0.005, init-value=0}
      RPortPrototype_TC11: nonqueued-receiver-com-spec{data-element=VariableDataPrototype_TC11, alive-timeout=0.005, handle-never-received=true, init-value=170}
      RPortPrototype_TC12: nonqueued-receiver-com-spec{data-element=VariableDataPrototype_TC12, alive-timeout=0.005, init-value=5}
      RPortPrototype_TC33: nonqueued-receiver-com-spec{data-element=VariableDataPrototype_TC33, alive-timeout=0.005, init-value=0}
      RPortPrototype_TC35: queued-receiver-com-spec{data-element=VariableDataPrototype_TC35, queue-length=5}
      RPortPrototype_TC42: nonqueued-receiver-com-spec{data-element=VariableDataPrototype_TC42, alive-timeout=0.005, enable-update=true, init-value=0}
      RPortPrototype_TC10: nonqueued-receiver-com-spec{data-element=VariableDataPrototype_TC10, alive-timeout=0.005, init-value=1}
    behavior SwcInternalBehavior_ExplicitIntra: handle-termination-and-restart=CAN-BE-TERMINATED-AND-RESTARTED
      timing event TimingEvent_RunnableEntity_ExplicitIntraReceive: start-on-event=RunnableEntity_ExplicitIntraReceive, period=5.0
      runnable RunnableEntity_ExplicitIntraReceive
        data-receive-point-by-arguments:
          6 x access:
            VariableAccess_TC2: accessed-variable={autosar-variable=RPortPrototype_TC2.VariableDataPrototype_TC2, local-variable=VariableDataPrototype_TC2}
            VariableAccess_TC11: accessed-variable={autosar-variable=RPortPrototype_TC11.VariableDataPrototype_TC11, local-variable=VariableDataPrototype_TC11}
            VariableAccess_TC12: accessed-variable={autosar-variable=RPortPrototype_TC12.VariableDataPrototype_TC12, local-variable=VariableDataPrototype_TC12}
            VariableAccess_TC35: accessed-variable={autosar-variable=RPortPrototype_TC35.VariableDataPrototype_TC35, local-variable=VariableDataPrototype_TC35}
            VariableAccess_TC42: accessed-variable={autosar-variable=RPortPrototype_TC42.VariableDataPrototype_TC42, local-variable=VariableDataPrototype_TC42}
            VariableAccess_TC10: accessed-variable={autosar-variable=RPortPrototype_TC10.VariableDataPrototype_TC10, local-variable=VariableDataPrototype_TC10}
        data-receive-point-by-values:
          access VariableAccess_TC33: accessed-variable={autosar-variable=RPortPrototype_TC33.VariableDataPrototype_TC33, local-variable=VariableDataPrototype_TC33}
  impl type uint8_queued: category=VALUE, base-type=uint8_base, sw-impl-policy=QUEUED, invalid-value=170, sw-is-virtual=false
package /ArPackage_IPDUgroups
  i signal i pdu group ISignalIPduGroup_TX: communication-direction=OUT, communication-mode=Debugging
    i-signal-i-pdus:
      ISignalIPdu_MMT_tx_201
      ISignalIPdu_MMT_tx_210
      ISignalIPdu_MMT_tx_211
      ISignalIPdu_MMT_tx_200
      ISignalIPdu_TC3U8Tx_120
      ISignalIPdu_TC5ArrTx_121
      ISignalIPdu_TC13U8Tx_126
      ISignalIPdu_TC14Arr8Tx_127
      ISignalIPdu_TC19U8Tx_12C
      ISignalIPdu_TC21U8Tx_250
      ISignalIPdu_TC23U8Tx_149
      ISignalIPdu_TC26Arr8Tx_12F
      ISignalIPdu_TC28Arr8Tx_252
      ISignalIPdu_TC30Arr8Tx_14B
      ISignalIPdu_TC36U8Tx_133
      ISignalIPdu_TC37U8Tx_254
      ISignalIPdu_TC22U8Tx_251
      ISignalIPdu_TC20U8Tx_12D
      ISignalIPdu_TC24U8Tx_14A
      ISignalIPdu_TC27Arr8Tx_130
      ISignalIPdu_TC29Arr8Tx_253
      ISignalIPdu_TC31Arr8Tx_14C
      ISignalIPdu_TC8DynArruint8_124
  i signal i pdu group ISignalIPduGroup_RX: communication-direction=IN, communication-mode=Debugging
    i-signal-i-pdus:
      ISignalIPdu_MMT_rx_202
      ISignalIPdu_MMT_rx_203
      ISignalIPdu_TC6U8Rx_122
      ISignalIPdu_TC7Arr8Rx_123
      ISignalIPdu_TC15U8RxInv_128
      ISignalIPdu_TC16U8RxInvReplace_129
      ISignalIPdu_TC17ArrRx_12A
      ISignalIPdu_TC18ArrRx_12B
      ISignalIPdu_TC34U8Rx_132
      ISignalIPdu_TC38U8Rx_134
      ISignalIPdu_TC32Arr8Rx_131
      ISignalIPdu_TC40U8Rx_136
      ISignalIPdu_TC41U8Rx_137
      ISignalIPdu_TC39Arr8Rx_135
      ISignalIPdu_TC9DynArruint8_125
      ISignalIPdu_TC25U8RX_12E
package /ArPackage_ExplicitInter
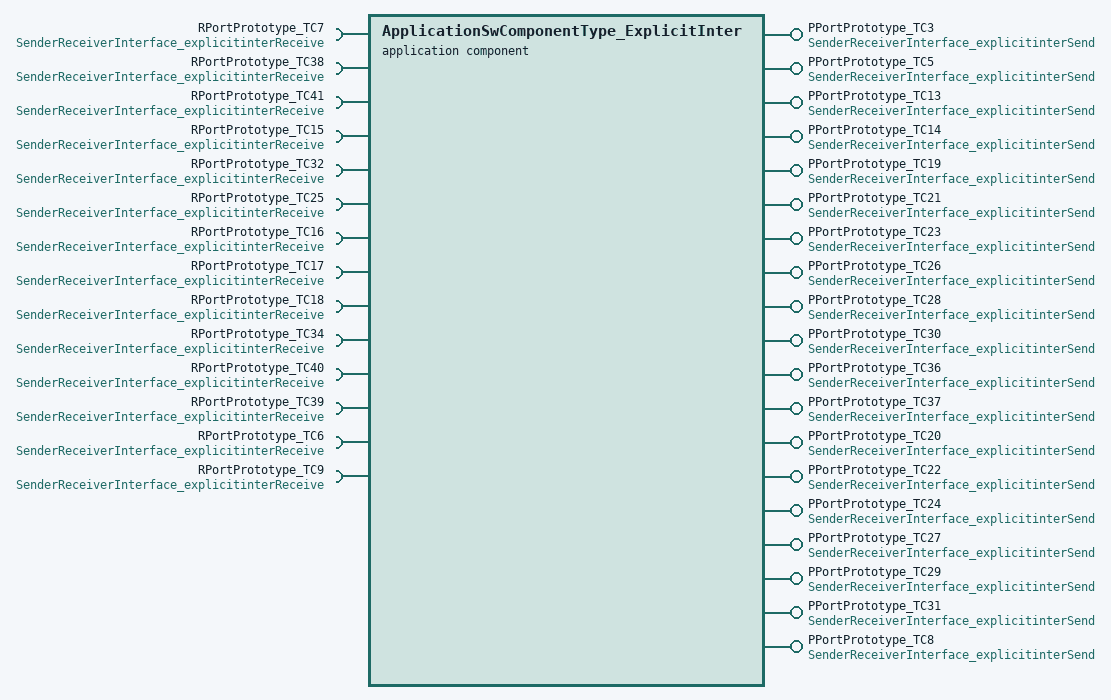
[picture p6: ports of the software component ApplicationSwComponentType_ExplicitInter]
  application sw component type ApplicationSwComponentType_ExplicitInter
    19 x provide port, all with provided-interface=SenderReceiverInterface_explicitinterSend:
      PPortPrototype_TC3: nonqueued-sender-com-spec=init-value=value:0
      PPortPrototype_TC5: nonqueued-sender-com-spec{data-element=VariableDataPrototype_TC5, init-value=5 x 1}
      PPortPrototype_TC13: nonqueued-sender-com-spec{data-element=VariableDataPrototype_TC13, init-value=value:0}
      PPortPrototype_TC14: nonqueued-sender-com-spec{data-element=VariableDataPrototype_TC14, init-value=5 x 1}
      PPortPrototype_TC19: nonqueued-sender-com-spec{data-element=VariableDataPrototype_TC19, transmission-acknowledge=timeout=5.0, init-value=value:0}
      PPortPrototype_TC21: nonqueued-sender-com-spec{data-element=VariableDataPrototype_TC21, transmission-acknowledge=timeout=7.0, init-value=value:0}
      PPortPrototype_TC23: nonqueued-sender-com-spec{data-element=VariableDataPrototype_TC23, transmission-acknowledge=timeout=7.0, init-value=value:0}
      PPortPrototype_TC26: nonqueued-sender-com-spec{data-element=VariableDataPrototype_TC26, transmission-acknowledge=timeout=7.0, init-value=5 x 1}
      PPortPrototype_TC28: nonqueued-sender-com-spec{data-element=VariableDataPrototype_TC28, transmission-acknowledge=timeout=7.0, init-value=5 x 1}
      PPortPrototype_TC30: nonqueued-sender-com-spec{data-element=VariableDataPrototype_TC30, transmission-acknowledge=timeout=7.0, init-value=5 x 1}
      PPortPrototype_TC36: queued-sender-com-spec{data-element=VariableDataPrototype_TC36, transmission-acknowledge=timeout=7.0}
      PPortPrototype_TC37: queued-sender-com-spec{data-element=VariableDataPrototype_TC37, transmission-acknowledge=timeout=7.0}
      PPortPrototype_TC20: nonqueued-sender-com-spec{data-element=VariableDataPrototype_TC20, transmission-acknowledge=timeout=5.0, init-value=value:0}
      PPortPrototype_TC22: nonqueued-sender-com-spec{data-element=VariableDataPrototype_TC22, transmission-acknowledge=timeout=5.0, init-value=value:0}
      PPortPrototype_TC24: nonqueued-sender-com-spec{data-element=VariableDataPrototype_TC24, transmission-acknowledge=timeout=5.0, init-value=value:0}
      PPortPrototype_TC27: nonqueued-sender-com-spec{data-element=VariableDataPrototype_TC27, transmission-acknowledge=timeout=5.0, init-value=5 x 1}
      PPortPrototype_TC29: nonqueued-sender-com-spec{data-element=VariableDataPrototype_TC29, transmission-acknowledge=timeout=5.0, init-value=5 x 1}
      PPortPrototype_TC31: nonqueued-sender-com-spec{data-element=VariableDataPrototype_TC31, transmission-acknowledge=timeout=5.0, init-value=5 x 1}
      PPortPrototype_TC8: nonqueued-sender-com-spec{data-element=VariableDataPrototype_TC8, init-value=8 x 0}
    14 x require port, all with required-interface=SenderReceiverInterface_explicitinterReceive:
      RPortPrototype_TC7: nonqueued-receiver-com-spec{data-element=VariableDataPrototype_TC7, alive-timeout=0.005, init-value=5 x 1}
      RPortPrototype_TC38: queued-receiver-com-spec{data-element=VariableDataPrototype_TC38, queue-length=3}
      RPortPrototype_TC41: nonqueued-receiver-com-spec{data-element=VariableDataPrototype_TC41, alive-timeout=0.005, enable-update=true, init-value=value:0}
      RPortPrototype_TC15: nonqueued-receiver-com-spec{data-element=VariableDataPrototype_TC15, alive-timeout=0.005, init-value=value:0}
      RPortPrototype_TC32: nonqueued-receiver-com-spec{data-element=VariableDataPrototype_TC32, alive-timeout=0.01, init-value=value:0}
      RPortPrototype_TC25: nonqueued-receiver-com-spec{data-element=VariableDataPrototype_TC25, alive-timeout=0.01, init-value=value:0}
      RPortPrototype_TC16: nonqueued-receiver-com-spec{data-element=VariableDataPrototype_TC16, alive-timeout=0.005, init-value=value:0}
      RPortPrototype_TC17: nonqueued-receiver-com-spec{data-element=VariableDataPrototype_TC17, alive-timeout=0.005, init-value=5 x 1}
      RPortPrototype_TC18: nonqueued-receiver-com-spec{data-element=VariableDataPrototype_TC18, alive-timeout=0.005, init-value=5 x 1}
      RPortPrototype_TC34: nonqueued-receiver-com-spec{data-element=VariableDataPrototype_TC34, alive-timeout=0.005, init-value=value:0}
      RPortPrototype_TC40: queued-receiver-com-spec{data-element=VariableDataPrototype_TC40, queue-length=3}
      RPortPrototype_TC39: queued-receiver-com-spec{data-element=VariableDataPrototype_TC39, queue-length=5}
      RPortPrototype_TC6: nonqueued-receiver-com-spec{data-element=VariableDataPrototype_TC6, alive-timeout=0.005, init-value=value:0}
      RPortPrototype_TC9: nonqueued-receiver-com-spec{data-element=VariableDataPrototype_TC9, alive-timeout=0.005, init-value=8 x 0}
    behavior SwcInternalBehavior_Inter: handle-termination-and-restart=CAN-BE-TERMINATED-AND-RESTARTED
      4 x data receive error event:
        DataReceiveErrorEvent_TC15: start-on-event=RunnableEntity_DREE, data=RPortPrototype_TC15.VariableDataPrototype_TC15
        DataReceiveErrorEvent_TC17: start-on-event=RunnableEntity_DREE, data=RPortPrototype_TC17.VariableDataPrototype_TC17
        DataReceiveErrorEvent_TC25: start-on-event=RunnableEntity_TC25AliveTimeOut, data=RPortPrototype_TC25.VariableDataPrototype_TC25
        DataReceiveErrorEvent_TC32: start-on-event=RunnableEntity_TC32AliveTimeout, data=RPortPrototype_TC32.VariableDataPrototype_TC32
      10 x data received event:
        DataReceivedEvent_TC6: start-on-event=RunnableEntity_DRE, data=RPortPrototype_TC6.VariableDataPrototype_TC6
        DataReceivedEvent_TC7: start-on-event=RunnableEntity_DRE, data=RPortPrototype_TC7.VariableDataPrototype_TC7
        DataReceivedEvent_TC16: start-on-event=RunnableEntity_DRE, data=RPortPrototype_TC16.VariableDataPrototype_TC16
        DataReceivedEvent_TC18: start-on-event=RunnableEntity_DRE, data=RPortPrototype_TC18.VariableDataPrototype_TC18
        DataReceivedEvent_TC34: start-on-event=RunnableEntity_DRE, data=RPortPrototype_TC34.VariableDataPrototype_TC34
        DataReceivedEvent_TC38: start-on-event=RunnableEntity_DRE, data=RPortPrototype_TC38.VariableDataPrototype_TC38
        DataReceivedEvent_TC41: start-on-event=RunnableEntity_DRE, data=RPortPrototype_TC41.VariableDataPrototype_TC41
        DataReceivedEvent_TC40: data=RPortPrototype_TC40.VariableDataPrototype_TC40
        DataReceivedEvent_TC39: start-on-event=RunnableEntity_DRE, data=RPortPrototype_TC39.VariableDataPrototype_TC39
        DataReceivedEvent_TC9: start-on-event=RunnableEntity_DRE, data=RPortPrototype_TC9.VariableDataPrototype_TC9
      14 x data send completed event:
        DataSendCompletedEvent_TC27_fdbck: event-source=VariableAccess_TC27
        DataSendCompletedEvent_TC29_fdbck: event-source=VariableAccess_TC29
        DataSendCompletedEvent_TC31_fdbck: event-source=VariableAccess_TC31
        DataSendCompletedEvent_TC23: start-on-event=RunnableEntity_TC23, event-source=VariableAccess_TC23
        DataSendCompletedEvent_TC19: start-on-event=RunnableEntity_TC19, event-source=VariableAccess_TC19
        DataSendCompletedEvent_TC21: start-on-event=RunnableEntity_TC21, event-source=VariableAccess_TC21
        DataSendCompletedEvent_TC26: start-on-event=RunnableEntity_TC26, event-source=VariableAccess_TC26
        DataSendCompletedEvent_TC28: start-on-event=RunnableEntity_TC28, event-source=VariableAccess_TC28
        DataSendCompletedEvent_TC30: start-on-event=RunnableEntity_TC30, event-source=VariableAccess_TC30
        DataSendCompletedEvent_TC36: start-on-event=RunnableEntity_TC36, event-source=VariableAccess_TC36
        DataSendCompletedEvent_TC37: start-on-event=RunnableEntity_TC37, event-source=VariableAccess_TC37
        DataSendCompletedEvent_TC20_fdbck
        DataSendCompletedEvent_TC22_fdbck
        DataSendCompletedEvent_TC24_fdbck
      18 x timing event, all with period=0.01:
        TimingEvent_RunnableEntity_TC27FeedbackWaitpoint: start-on-event=RunnableEntity_TC27FeedbackWaitpoint
        TimingEvent_RunnableEntity_TC29: start-on-event=RunnableEntity_TC29
        TimingEvent_RunnableEntity_TC29FeedbackWaitpoint: start-on-event=RunnableEntity_TC29FeedbackWaitpoint
        TimingEvent_RunnableEntity_TxTOut: start-on-event=RunnableEntity_TxTOut
        TimingEvent_RunnableEntity_TC31: start-on-event=RunnableEntity_TC31
        TimingEvent_RunnableEntity_TC31FeedbackWaitpoint: start-on-event=RunnableEntity_TC31FeedbackWaitpoint
        TimingEvent_RunnableEntity_TC20: start-on-event=RunnableEntity_TC20
        TimingEvent_RunnableEntity_TC40: start-on-event=RunnableEntity_TC40
        TimingEvent_RunnableEntity_TC20FeedbackWaitPoint: start-on-event=RunnableEntity_TC20FeedbackWaitPoint
        TimingEvent_RunnableEntity_TC21: start-on-event=RunnableEntity_TC21
        TimingEvent_RunnableEntity_TC22: start-on-event=RunnableEntity_TC22
        TimingEvent_RunnableEntity_ExplicitInterSend: start-on-event=RunnableEntity_ExplicitInterSend
        TimingEvent_RunnableEntity_TC22FeedbackWaitPoint: start-on-event=RunnableEntity_TC22FeedbackWaitpoint
        TimingEvent_RunnableEntity_TC24: start-on-event=RunnableEntity_TC24
        TimingEvent_RunnableEntity_TxAck: start-on-event=RunnableEntity_TxAck
        TimingEvent_RunnableEntity_TC24FeedbackWaitpoint: start-on-event=RunnableEntity_TC24FeedbackWaitpoint
        TimingEvent_RunnableEntity_TxErr: start-on-event=RunnableEntity_TxErr
        TimingEvent_RunnableEntity_TC27: start-on-event=RunnableEntity_TC27
      29 x runnable:
        RunnableEntity_ExplicitInterSend
          data-send-points:
            5 x access:
              VariableAccess_TC3: accessed-variable={autosar-variable=PPortPrototype_TC3.VariableDataPrototype_TC3, local-variable=VariableDataPrototype_TC3}
              VariableAccess_TC5: accessed-variable={autosar-variable=PPortPrototype_TC5.VariableDataPrototype_TC5, local-variable=VariableDataPrototype_TC5}
              VariableAccess_TC13: accessed-variable={autosar-variable=PPortPrototype_TC13.VariableDataPrototype_TC13, local-variable=VariableDataPrototype_TC13}
              VariableAccess_TC14: accessed-variable={autosar-variable=PPortPrototype_TC14.VariableDataPrototype_TC14, local-variable=VariableDataPrototype_TC14}
              VariableAccess_TC8: accessed-variable={autosar-variable=PPortPrototype_TC8.VariableDataPrototype_TC8, local-variable=VariableDataPrototype_TC8}
        RunnableEntity_DRE
          data-receive-point-by-arguments:
            8 x access:
              VariableAccess_TC6: accessed-variable={autosar-variable=RPortPrototype_TC6.VariableDataPrototype_TC6, local-variable=VariableDataPrototype_TC6}
              VariableAccess_TC7: accessed-variable={autosar-variable=RPortPrototype_TC7.VariableDataPrototype_TC7, local-variable=VariableDataPrototype_TC7}
              VariableAccess_TC16: accessed-variable={autosar-variable=RPortPrototype_TC16.VariableDataPrototype_TC16, local-variable=VariableDataPrototype_TC16}
              VariableAccess_TC18: accessed-variable={autosar-variable=RPortPrototype_TC18.VariableDataPrototype_TC18, local-variable=VariableDataPrototype_TC18}
              VariableAccess_TC38: accessed-variable={autosar-variable=RPortPrototype_TC38.VariableDataPrototype_TC38, local-variable=VariableDataPrototype_TC6}
              VariableAccess_TC41: accessed-variable={autosar-variable=RPortPrototype_TC41.VariableDataPrototype_TC41, local-variable=VariableDataPrototype_TC6}
              VariableAccess_TC39: accessed-variable={autosar-variable=RPortPrototype_TC39.VariableDataPrototype_TC39, local-variable=VariableDataPrototype_TC39}
              VariableAccess_TC9: accessed-variable={autosar-variable=RPortPrototype_TC9.VariableDataPrototype_TC9, local-variable=VariableDataPrototype_TC9}
          data-receive-point-by-values:
            access VariableAccess_TC34: accessed-variable={autosar-variable=RPortPrototype_TC34.VariableDataPrototype_TC34, local-variable=VariableDataPrototype_TC6}
        RunnableEntity_DREE
          data-receive-point-by-arguments:
            access VariableAccess_TC15: accessed-variable={autosar-variable=RPortPrototype_TC15.VariableDataPrototype_TC15, local-variable=VariableDataPrototype_TC15}
            access VariableAccess_TC17: accessed-variable={autosar-variable=RPortPrototype_TC17.VariableDataPrototype_TC17, local-variable=VariableDataPrototype_TC17}
        RunnableEntity_TxAck
          data-send-points:
            access VariableAccess_TC19: accessed-variable=PPortPrototype_TC19.VariableDataPrototype_TC19
            access VariableAccess_TC26: accessed-variable={autosar-variable=PPortPrototype_TC26.VariableDataPrototype_TC26, local-variable=VariableDataPrototype_TC5}
            access VariableAccess_TC36: accessed-variable={autosar-variable=PPortPrototype_TC36.VariableDataPrototype_TC36, local-variable=VariableDataPrototype_TC3}
        RunnableEntity_TC19
        RunnableEntity_TxErr
          data-send-points:
            access VariableAccess_TC21: accessed-variable={autosar-variable=PPortPrototype_TC21.VariableDataPrototype_TC21, local-variable=VariableDataPrototype_TC3}
            access VariableAccess_TC28: accessed-variable={autosar-variable=PPortPrototype_TC28.VariableDataPrototype_TC28, local-variable=VariableDataPrototype_TC5}
            access VariableAccess_TC37: accessed-variable={autosar-variable=PPortPrototype_TC37.VariableDataPrototype_TC37, local-variable=VariableDataPrototype_TC3}
        RunnableEntity_TC21: can-be-invoked-concurrently=true
        RunnableEntity_TxTOut
          data-send-points:
            access VariableAccess_TC23: accessed-variable={autosar-variable=PPortPrototype_TC23.VariableDataPrototype_TC23, local-variable=VariableDataPrototype_TC3}
            access VariableAccess_TC30: accessed-variable={autosar-variable=PPortPrototype_TC30.VariableDataPrototype_TC30, local-variable=VariableDataPrototype_TC5}
        RunnableEntity_TC23
        RunnableEntity_TC25AliveTimeOut
        RunnableEntity_TC26
        RunnableEntity_TC28
        RunnableEntity_TC30
        RunnableEntity_TC36
        RunnableEntity_TC37
        RunnableEntity_TC20: symbol=RUNTC20
          data-send-points:
            access VariableAccess_TC20: accessed-variable={autosar-variable=PPortPrototype_TC20.VariableDataPrototype_TC20, local-variable=VariableDataPrototype_TC3}
        RunnableEntity_TC20FeedbackWaitPoint
          wait point WaitPoint_TC20: timeout=5.0, trigger=DataSendCompletedEvent_TC20_fdbck
        RunnableEntity_TC32AliveTimeout: symbol=RunnableEntity_TC32AliveTimeOut
        RunnableEntity_TC22
          data-send-points:
            access VariableAccess_TC22: accessed-variable={autosar-variable=PPortPrototype_TC22.VariableDataPrototype_TC22, local-variable=VariableDataPrototype_TC3}
        RunnableEntity_TC22FeedbackWaitpoint
          wait point WaitPoint_TC22: timeout=5.0, trigger=DataSendCompletedEvent_TC22_fdbck
        RunnableEntity_TC24
          data-send-points:
            access VariableAccess_TC24: accessed-variable={autosar-variable=PPortPrototype_TC24.VariableDataPrototype_TC24, local-variable=VariableDataPrototype_TC3}
        RunnableEntity_TC24FeedbackWaitpoint
          wait point WaitPoint_TC24: timeout=5.0, trigger=DataSendCompletedEvent_TC24_fdbck
        RunnableEntity_TC27
          data-send-points:
            access VariableAccess_TC27: accessed-variable={autosar-variable=PPortPrototype_TC27.VariableDataPrototype_TC27, local-variable=VariableDataPrototype_TC5}
        RunnableEntity_TC27FeedbackWaitpoint
          wait point WaitPoint_TC27: timeout=5.0, trigger=DataSendCompletedEvent_TC27_fdbck
        RunnableEntity_TC29
          data-send-points:
            access VariableAccess_TC29: accessed-variable={autosar-variable=PPortPrototype_TC29.VariableDataPrototype_TC29, local-variable=VariableDataPrototype_TC5}
        RunnableEntity_TC29FeedbackWaitpoint
          wait point WaitPoint_TC29: timeout=5.0, trigger=DataSendCompletedEvent_TC29_fdbck
        RunnableEntity_TC31
          data-send-points:
            access VariableAccess_TC31: accessed-variable={autosar-variable=PPortPrototype_TC31.VariableDataPrototype_TC31, local-variable=VariableDataPrototype_TC5}
        RunnableEntity_TC31FeedbackWaitpoint
          wait point WaitPoint_TC31: timeout=5.0, trigger=DataSendCompletedEvent_TC31_fdbck
        RunnableEntity_TC40
          data-receive-point-by-arguments:
            access VariableAccess_TC40: accessed-variable={autosar-variable=RPortPrototype_TC40.VariableDataPrototype_TC40, local-variable=VariableDataPrototype_TC40}
          wait point WaitPoint_TC40: timeout=5.0, trigger=DataReceivedEvent_TC40
  sender receiver interface SenderReceiverInterface_explicitinterSend
    19 x data:
      VariableDataPrototype_TC3: type=uint8_ExpInter
      VariableDataPrototype_TC5: type=Arruint8
      VariableDataPrototype_TC13: type=uint8_ExpInter
      VariableDataPrototype_TC14: type=Arruint8
      VariableDataPrototype_TC{19..24}: type=uint8_ExpInter
      VariableDataPrototype_TC{26..31}: type=Arruint8
      VariableDataPrototype_TC36: type=uint8_ExpInter_queued
      VariableDataPrototype_TC37: type=uint8_ExpInter_queued
      VariableDataPrototype_TC8: type=DynArruint8
    invalidation-policys:
      data-element=VariableDataPrototype_TC13, handle-invalid=KEEP
      data-element=VariableDataPrototype_TC14, handle-invalid=KEEP
  impl type uint8_ExpInter: category=VALUE, base-type=uint8_base, invalid-value=170, sw-is-virtual=false
  impl type Arruint8: category=ARRAY
    element ImplementationDataTypeElement_ArrU8: array-size=5, array-size-semantics=FIXED-SIZE, implementation-data-type=uint8_ExpInter, invalid-value=170, sw-is-virtual=false
  impl type DynArruint8: category=ARRAY
    element ImplementationDataTypeElement_DynArruint8: array-size=8, array-size-semantics=VARIABLE-SIZE, implementation-data-type=uint8_ExpInter, sw-is-virtual=false
  sender receiver interface SenderReceiverInterface_explicitinterReceive
    14 x data:
      VariableDataPrototype_TC6: type=uint8_ExpInter
      VariableDataPrototype_TC7: type=Arruint8
      VariableDataPrototype_TC15: type=uint8_ExpInter
      VariableDataPrototype_TC16: type=uint8_ExpInter
      VariableDataPrototype_TC17: type=Arruint8
      VariableDataPrototype_TC18: type=Arruint8
      VariableDataPrototype_TC25: type=uint8_ExpInter
      VariableDataPrototype_TC34: type=uint8_ExpInter
      VariableDataPrototype_TC38: type=uint8_ExpInter_queued
      VariableDataPrototype_TC41: type=uint8_ExpInter
      VariableDataPrototype_TC32: type=uint8_ExpInter
      VariableDataPrototype_TC40: type=uint8_ExpInter_queued
      VariableDataPrototype_TC39: type=Arruint8_queued
      VariableDataPrototype_TC9: type=DynArruint8
    invalidation-policys:
      data-element=VariableDataPrototype_TC15, handle-invalid=KEEP
      data-element=VariableDataPrototype_TC16, handle-invalid=REPLACE
      data-element=VariableDataPrototype_TC17, handle-invalid=KEEP
      data-element=VariableDataPrototype_TC18, handle-invalid=REPLACE
  system signal SystemSignal_TC17Arr0Rx
  system signal SystemSignal_TC17Arr1Rx
  system signal SystemSignal_TC32Arr0Rx
  system signal SystemSignal_TC32Arr1Rx
  impl type uint8_ExpInter_queued: category=VALUE, base-type=uint8_base, sw-impl-policy=QUEUED, invalid-value=170, sw-is-virtual=false
  system signal SystemSignal_TC26Arr0Tx
  system signal SystemSignal_TC26Arr1Tx
  system signal SystemSignal_TC28Arr0Tx
  system signal SystemSignal_TC28Arr1Tx
  system signal SystemSignal_TC30Arr0Tx
  system signal SystemSignal_TC30Arr1Tx
  system signal SystemSignal_TC27Arr{0..2}Tx
  system signal SystemSignal_TC29Arr0Tx
  system signal SystemSignal_TC29Arr1Tx
  system signal SystemSignal_TC31Arr0Tx
  system signal SystemSignal_TC31Arr1Tx
  impl type Arruint8_queued: category=ARRAY, sw-impl-policy=QUEUED
    element ImplementationDataTypeElement_ArrU8: array-size=5, array-size-semantics=FIXED-SIZE, implementation-data-type=uint8_ExpInter, invalid-value=170, sw-is-virtual=false
  system signal SystemSignal_TC14Arr{0..2}TX
  system signal SystemSignal_TC7Arr{0..2}RX
  system signal SystemSignal_TC5Arr{0..2}TX
  i signal group ISignalGroup_TC5ArrTx_121: system-signal-group=SystemSignalGroup_TC5ArrTx_121
  i signal group ISignalGroup_TC14Arr8Tx_127: system-signal-group=SystemSignalGroup_TC14Arr8Tx_127
  i signal group ISignalGroup_TC26Arr8Tx_12F: system-signal-group=SystemSignalGroup_TC26Arr8Tx_12F
  i signal group ISignalGroup_TC28Arr8Tx_252: system-signal-group=SystemSignalGroup_TC28Arr8Tx_252
  i signal group ISignalGroup_TC31Arr8Tx_14C: system-signal-group=SystemSignalGroup_TC31Arr8Tx_14C
  i signal group ISignalGroup_TC30Arr8Tx_14B: system-signal-group=SystemSignalGroup_TC30Arr8Tx_14B
  i signal group ISignalGroup_TC27Arr8Tx_130: system-signal-group=SystemSignalGroup_TC27Arr8Tx_130
  i signal group ISignalGroup_TC29Arr8Tx_253: system-signal-group=SystemSignalGroup_TC29Arr8Tx_253
  i signal group ISignalGroup_TC7ArrRx_123: system-signal-group=SystemSignalGroup_TC7ArrRx_123
  i signal group ISignalGroup_TC17Arr8Rx_12A: system-signal-group=SystemSignaGroupl_TC17Arr8Rx_12A
  i signal group ISignalGroup_TC18Arr8Rx_12B: system-signal-group=SystemSignalGroup_TC18Arr8Rx_12B
  system signal SystemSignal_TC18Arr{0..2}Rx
  i signal group ISignalGroup_TC32Arr8Rx_131: system-signal-group=SystemSignalGroup_TC32Arr8Rx_131
  i signal group ISignalGroup_TC39Arr8Rx_135: system-signal-group=SystemSignalGroup_TC39Arr8Rx_135
  system signal SystemSignal_TC39Arr{0..2}Rx
